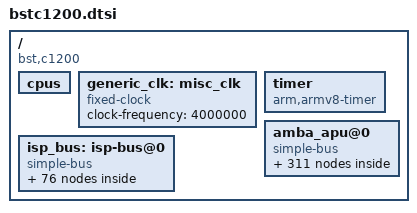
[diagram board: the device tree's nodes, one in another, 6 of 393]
// SPDX-License-Identifier: GPL-2.0+
/*
 * dts file for BlackSesame C1200
 *
 * (C) Copyright 2016 - 2024, BlackSesame, Inc.
 *
 * This program is free software; you can redistribute it and/or
 * modify it under the terms of the GNU General Public License as
 * published by the Free Software Foundation; either version 2 of
 * the License, or (at your option) any later version.
 */
#include <dt-bindings/interrupt-controller/arm-gic.h>
#include <dt-bindings/gpio/gpio.h>
#include <dt-bindings/clock/bstc1200-scmi.h>
#include <dt-bindings/reset/bst-resets-scmi.h>

/ {
	compatible = "bst,c1200";
	#address-cells = <2>;
	#size-cells = <2>;

	cpus {
		#address-cells = <1>;
		#size-cells = <0>;
	};

	generic_clk:misc_clk {
		compatible = "fixed-clock";
		#clock-cells = <0x0>;
		clock-frequency = <4000000>;
		phandle = <0x2>;
	};


	timer {
		compatible = "arm,armv8-timer";
		interrupt-parent = <&gic600>;
		interrupts = <GIC_PPI 0xd (GIC_CPU_MASK_SIMPLE(8) | IRQ_TYPE_LEVEL_LOW)
						GIC_PPI 0xe (GIC_CPU_MASK_SIMPLE(8) | IRQ_TYPE_LEVEL_LOW)
						GIC_PPI 0xb (GIC_CPU_MASK_SIMPLE(8) | IRQ_TYPE_LEVEL_LOW)
						GIC_PPI 0xa (GIC_CPU_MASK_SIMPLE(8) | IRQ_TYPE_LEVEL_LOW)>;
	};




	amba_apu@0 {
		compatible = "simple-bus";
		#address-cells = <0x2>;
		#size-cells = <0x2>;
		ranges = <0x0 0x0 0x0 0x0 0xffffffff 0xffffffff>;

		cpufreq: cpufreq@0 {
			compatible = "bst,cpufreq-c1200";
			reg = <0 0x30002000 0 0x1000>;
			clocks= <&scmi_clk GATE_CPU0_MP4_CORE_EN>,
				<&scmi_clk GATE_LB_CPU1_MP4_CORE_CLK_EN>,
				<&scmi_clk GATE_LB_CPU_MP2_CORE_CLK_EN>;
			clock-names = "cluster0", "cluster1", "cluster2";
			#freq-domain-cells = <1>;
		};

		bst_hfe: hfe@0x2300b000 {
			compatible = "bst,c1200-hfe";
			status = "disable";
			reg = <0x0 0x2300b000 0x0 0x1000>;
			interrupt-parent = <&gic600>;
			interrupts = <GIC_SPI 193 IRQ_TYPE_LEVEL_HIGH>;
		};
		bst_ske: ske@0x2300a000 {
			compatible = "bst,c1200-ske";
			status = "disable";
			reg = <0x0 0x2300a000 0x0 0x1000>;
			interrupt-parent = <&gic600>;
			interrupts = <GIC_SPI 194 IRQ_TYPE_LEVEL_HIGH>;
		};
		bst_pke: pke@0x23008000 {
			compatible = "bst,c1200-pke";
			status = "disable";
			reg = <0x0 0x23008000 0x0 0x2000>;
			interrupt-parent = <&gic600>;
			interrupts = <GIC_SPI 195 IRQ_TYPE_LEVEL_HIGH>;
		};

		msgbox: bst-msgbox {
			status = "disable";
			compatible = "bst,bst-msgbox";
			reg =   <0x0 0x32a00000 0 0x100000>;
			interrupt-parent = <&gic600>;
			#mbox-cells = <0x1>;
		};

		hwrng: bst-rng {
			status = "disable";
			compatible = "bst,c1200-rng";
		};

	safety_command:safety{
        compatible = "bst,safety_command";
        status = "disable";
    };

	firmware_scmi:scmi {
		compatible = "arm,scmi-msgbox";
		#address-cells = <1>;
		#size-cells = <0>;
		status = "disable";

		scmi_devpd: protocol@11 {
				reg = <0x11>;
				#power-domain-cells = <1>;
		};

		scmi_reset:protocol@16 {
			reg=<0x16>;
			#reset-cells =<1>;
		};

		scmi_clk:protocol@14 {
			reg=<0x14>;
			#clock-cells=<1>;
		};

		scmi_voltage: protocol@17 {
			reg = <0x17>;
		};

		scmi_pinctrl: protocol@19 {
			reg = <0x19>;
			#pinctrl-cells = <0>;
			i2c5_pinctrl: i2c5_pinctrl {
				mux {
					pins = "SC_I2C5_SCL", "SC_I2C5_SDA";
					function = "i2c5";
				};
			};
			i2c6_pinctrl: i2c6_pinctrl {
				mux {
					pins = "SC_I2C6_SCL", "SC_I2C6_SDA";
					function = "i2c6";
				};
			};
			i2c7_pinctrl: i2c7_pinctrl {
				mux {
					pins = "SC_I2C7_SCL", "SC_I2C7_SDA";
					function = "i2c7";
				};
			};
        };

		
		scmi_channel:protocol@1a {
			reg=<0x1a>;
			#reset-cells =<1>;
		};
	};

                gdma0:dma-controller@31280000 {
                        #dma-cells = <1>;
                        status = "disable";
                        compatible = "bst,dw-axi-gdma";
                        reg = <0x0 0x31280000 0 0x3000>;
                        //clocks = <&clkc LB_GDMA_CORE_CLK>, <&clkc LB_GDMA_AXI_GACLK>;
                        //clock-names = "core-clk", "cfgr-clk";
                        //resets = <&rstc RST_GDMA_SW>;
                        //reset-names = "gdma_reset";
			snps,chan-start = <0>;
                        dma-channels = <32>;
                        snps,dma-masters = <1>;
                        snps,data-width = <4>;
                        snps,block-size = <1048576 1048576 1048576 1048576 1048576 1048576 1048576 1048576
                                           1048576 1048576 1048576 1048576 1048576 1048576 1048576 1048576
                                           1048576 1048576 1048576 1048576 1048576 1048576 1048576 1048576
                                           1048576 1048576 1048576 1048576 1048576 1048576 1048576 1048576>;

                        snps,priority = <31 30 29 28 27 26 25 24
                                                         23 22 21 20 19 18 17 16
                                                         15 14 13 12 11 10  9  8
                                                          7  6  5  4  3  2  1  0>;
                        snps,axi-max-burst-len = <15>;
                        interrupt-parent = <&gic600>;
			interrupts = <            GIC_SPI 385 (GIC_CPU_MASK_SIMPLE(8) | IRQ_TYPE_LEVEL_HIGH)
                                                  GIC_SPI 386 (GIC_CPU_MASK_SIMPLE(8) | IRQ_TYPE_LEVEL_HIGH)
                                                  GIC_SPI 387 (GIC_CPU_MASK_SIMPLE(8) | IRQ_TYPE_LEVEL_HIGH)
                                                  GIC_SPI 388 (GIC_CPU_MASK_SIMPLE(8) | IRQ_TYPE_LEVEL_HIGH)
                                                  GIC_SPI 389 (GIC_CPU_MASK_SIMPLE(8) | IRQ_TYPE_LEVEL_HIGH)
                                                  GIC_SPI 390 (GIC_CPU_MASK_SIMPLE(8) | IRQ_TYPE_LEVEL_HIGH)
                                                  GIC_SPI 391 (GIC_CPU_MASK_SIMPLE(8) | IRQ_TYPE_LEVEL_HIGH)
                                                  GIC_SPI 392 (GIC_CPU_MASK_SIMPLE(8) | IRQ_TYPE_LEVEL_HIGH)
                                                  GIC_SPI 393 (GIC_CPU_MASK_SIMPLE(8) | IRQ_TYPE_LEVEL_HIGH)
                                                  GIC_SPI 394 (GIC_CPU_MASK_SIMPLE(8) | IRQ_TYPE_LEVEL_HIGH)
                                                  GIC_SPI 395 (GIC_CPU_MASK_SIMPLE(8) | IRQ_TYPE_LEVEL_HIGH)
                                                  GIC_SPI 396 (GIC_CPU_MASK_SIMPLE(8) | IRQ_TYPE_LEVEL_HIGH)
                                                  GIC_SPI 397 (GIC_CPU_MASK_SIMPLE(8) | IRQ_TYPE_LEVEL_HIGH)
                                                  GIC_SPI 398 (GIC_CPU_MASK_SIMPLE(8) | IRQ_TYPE_LEVEL_HIGH)
                                                  GIC_SPI 399 (GIC_CPU_MASK_SIMPLE(8) | IRQ_TYPE_LEVEL_HIGH)
                                                  GIC_SPI 400 (GIC_CPU_MASK_SIMPLE(8) | IRQ_TYPE_LEVEL_HIGH)
                                                  GIC_SPI 401 (GIC_CPU_MASK_SIMPLE(8) | IRQ_TYPE_LEVEL_HIGH)
                                                  GIC_SPI 402 (GIC_CPU_MASK_SIMPLE(8) | IRQ_TYPE_LEVEL_HIGH)
                                                  GIC_SPI 403 (GIC_CPU_MASK_SIMPLE(8) | IRQ_TYPE_LEVEL_HIGH)
                                                  GIC_SPI 404 (GIC_CPU_MASK_SIMPLE(8) | IRQ_TYPE_LEVEL_HIGH)
                                                  GIC_SPI 405 (GIC_CPU_MASK_SIMPLE(8) | IRQ_TYPE_LEVEL_HIGH)
                                                  GIC_SPI 406 (GIC_CPU_MASK_SIMPLE(8) | IRQ_TYPE_LEVEL_HIGH)
                                                  GIC_SPI 407 (GIC_CPU_MASK_SIMPLE(8) | IRQ_TYPE_LEVEL_HIGH)
                                                  GIC_SPI 408 (GIC_CPU_MASK_SIMPLE(8) | IRQ_TYPE_LEVEL_HIGH)
                                                  GIC_SPI 409 (GIC_CPU_MASK_SIMPLE(8) | IRQ_TYPE_LEVEL_HIGH)
                                                  GIC_SPI 410 (GIC_CPU_MASK_SIMPLE(8) | IRQ_TYPE_LEVEL_HIGH)
                                                  GIC_SPI 411 (GIC_CPU_MASK_SIMPLE(8) | IRQ_TYPE_LEVEL_HIGH)
                                                  GIC_SPI 412 (GIC_CPU_MASK_SIMPLE(8) | IRQ_TYPE_LEVEL_HIGH)
                                                  GIC_SPI 413 (GIC_CPU_MASK_SIMPLE(8) | IRQ_TYPE_LEVEL_HIGH)
                                                  GIC_SPI 414 (GIC_CPU_MASK_SIMPLE(8) | IRQ_TYPE_LEVEL_HIGH)
                                                  GIC_SPI 415 (GIC_CPU_MASK_SIMPLE(8) | IRQ_TYPE_LEVEL_HIGH)
                                                  GIC_SPI 416 (GIC_CPU_MASK_SIMPLE(8) | IRQ_TYPE_LEVEL_HIGH)>;
                };



// Cfg_LIO_system	0:2000:0000
// lsp0_crm_reg 2000:0000
		i2c0: i2c@20001000 {
			#address-cells = <1>;
			#size-cells = <0>;
			compatible = "snps,designware-i2c";
			reg = <0x0 0x20001000 0 0x1000>;
			interrupt-parent = <&gic600>;
			interrupts = <GIC_SPI 202 IRQ_TYPE_LEVEL_HIGH>;
			clock-frequency = <100000>;
			i2c-sda-hold-time-ns = <560>;
			i2c-sda-falling-time-ns = <560>;
			i2c-scl-falling-time-ns = <560>;
			i2c-digital-filter-width-ns = <50>;
			
			clocks= <&scmi_clk GATE_LSP0_I2C0_PCLK_EN>,
			<&scmi_clk GATE_LSP0_I2C0_WCLK_EN>;
			clock-names = "pclk","wclk";
			resets = <&scmi_reset RST_LSP0_I2C0_WCLK_SW>;
			reset-names = "i2c0_reset";

			i2c-nr = <0>;
			status = "disable";
		};

		i2c1: i2c@20002000 {
			#address-cells = <1>;
			#size-cells = <0>;
			compatible = "snps,designware-i2c";
			reg = <0x0 0x20002000 0 0x1000>;
			interrupt-parent = <&gic600>;
			interrupts = <GIC_SPI 203 IRQ_TYPE_LEVEL_HIGH>;
			clock-frequency = <100000>;
			i2c-sda-hold-time-ns = <560>;
			i2c-sda-falling-time-ns = <560>;
			i2c-scl-falling-time-ns = <560>;
			i2c-digital-filter-width-ns = <50>;

			clocks= <&scmi_clk GATE_LSP0_I2C1_PCLK_EN>,
			<&scmi_clk GATE_LSP0_I2C1_WCLK_EN>;
			clock-names = "pclk","wclk";
			resets = <&scmi_reset RST_LSP0_I2C1_WCLK_SW>;
			reset-names = "i2c0_reset";

			i2c-nr = <1>;
			status = "disable";
		};

		i2c2: i2c@20003000 {
			#address-cells = <1>;
			#size-cells = <0>;
			compatible = "snps,designware-i2c";
			reg = <0x0 0x20003000 0 0x1000>;
			interrupt-parent = <&gic600>;
			interrupts = <GIC_SPI 204 IRQ_TYPE_LEVEL_HIGH>;
			clock-frequency = <100000>;
			i2c-sda-hold-time-ns = <560>;
			i2c-sda-falling-time-ns = <560>;
			i2c-scl-falling-time-ns = <560>;
			i2c-digital-filter-width-ns = <50>;

			clocks= <&scmi_clk GATE_LSP0_I2C2_PCLK_EN>,
			<&scmi_clk GATE_LSP0_I2C2_WCLK_EN>;
			clock-names = "pclk","wclk";
			resets = <&scmi_reset RST_LSP0_I2C2_WCLK_SW>;
			reset-names = "i2c0_reset";

			i2c-nr = <2>;
			status = "disable";
		};



		i2c3: i2c@20004000 {
			#address-cells = <1>;
			#size-cells = <0>;
			compatible = "snps,designware-i2c";
			reg = <0x0 0x20004000 0 0x1000>;
			interrupt-parent = <&gic600>;
			interrupts = <GIC_SPI 205 IRQ_TYPE_LEVEL_HIGH>;
			clock-frequency = <100000>;
			i2c-sda-hold-time-ns = <560>;
			i2c-sda-falling-time-ns = <560>;
			i2c-scl-falling-time-ns = <560>;
			i2c-digital-filter-width-ns = <50>;

			clocks= <&scmi_clk GATE_LSP0_I2C3_PCLK_EN>,
			<&scmi_clk GATE_LSP0_I2C3_WCLK_EN>;
			clock-names = "pclk","wclk";
			resets = <&scmi_reset RST_LSP0_I2C3_WCLK_SW>;
			reset-names = "i2c0_reset";

			i2c-nr = <3>;
			status = "disable";
		};

		i2c4: i2c@20021000 {
			#address-cells = <1>;
			#size-cells = <0>;
			compatible = "snps,designware-i2c";
			reg = <0x0 0x20021000 0 0x1000>;
			interrupt-parent = <&gic600>;
			interrupts = <GIC_SPI 237 IRQ_TYPE_LEVEL_HIGH>;
			clock-frequency = <100000>;
			i2c-sda-hold-time-ns = <560>;
			i2c-sda-falling-time-ns = <560>;
			i2c-scl-falling-time-ns = <560>;
			i2c-digital-filter-width-ns = <50>;

			clocks= <&scmi_clk GATE_LSP1_I2C0_PCLK_EN>,
			<&scmi_clk GATE_LSP1_I2C0_WCLK_EN>;
			clock-names = "pclk","wclk";
			resets = <&scmi_reset RST_LSP1_I2C0_WCLK_SW>;
			reset-names = "i2c0_reset";

			i2c-nr = <4>;
			status = "disable";
		};

		i2c5: i2c@20022000 {
			#address-cells = <1>;
			#size-cells = <0>;
			compatible = "snps,designware-i2c";
			reg = <0x0 0x20022000 0 0x1000>;
			interrupt-parent = <&gic600>;
			interrupts = <GIC_SPI 238 IRQ_TYPE_LEVEL_HIGH>;
			clock-frequency = <100000>;
			i2c-sda-hold-time-ns = <560>;
			i2c-sda-falling-time-ns = <560>;
			i2c-scl-falling-time-ns = <560>;
			i2c-digital-filter-width-ns = <50>;

			clocks= <&scmi_clk GATE_LSP1_I2C1_PCLK_EN>,
			<&scmi_clk GATE_LSP1_I2C1_WCLK_EN>;
			clock-names = "pclk","wclk";
			resets = <&scmi_reset RST_LSP1_I2C1_WCLK_SW>;
			reset-names = "i2c0_reset";

			i2c-nr = <5>;
			ipc-sem = <1 1 7>;
			pinctrl-names = "default";
			pinctrl-0 = <&i2c5_pinctrl>;
			status = "disable";
		};

		i2c6: i2c@20023000 {
			#address-cells = <1>;
			#size-cells = <0>;
			compatible = "snps,designware-i2c";
			reg = <0x0 0x20023000 0 0x1000>;
			interrupt-parent = <&gic600>;
			interrupts = <GIC_SPI 239 IRQ_TYPE_LEVEL_HIGH>;
			clock-frequency = <100000>;
			i2c-sda-hold-time-ns = <560>;
			i2c-sda-falling-time-ns = <560>;
			i2c-scl-falling-time-ns = <560>;
			i2c-digital-filter-width-ns = <50>;

			clocks= <&scmi_clk GATE_LSP1_I2C2_PCLK_EN>,
			<&scmi_clk GATE_LSP1_I2C2_WCLK_EN>;
			clock-names = "pclk","wclk";
			resets = <&scmi_reset RST_LSP1_I2C2_WCLK_SW>;
			reset-names = "i2c0_reset";

			i2c-nr = <6>;
			ipc-sem = <1 1 8>;
			pinctrl-names = "default";
			pinctrl-0 = <&i2c6_pinctrl>;
			status = "disable";
		};

		i2c7: i2c@20024000 {
			#address-cells = <1>;
			#size-cells = <0>;
			compatible = "snps,designware-i2c";
			reg = <0x0 0x20024000 0 0x1000>;
			interrupt-parent = <&gic600>;
			interrupts = <GIC_SPI 240 IRQ_TYPE_LEVEL_HIGH>;
			clock-frequency = <100000>;
			i2c-sda-hold-time-ns = <560>;
			i2c-sda-falling-time-ns = <560>;
			i2c-scl-falling-time-ns = <560>;
			i2c-digital-filter-width-ns = <50>;

			clocks= <&scmi_clk GATE_LSP1_I2C3_PCLK_EN>,
			<&scmi_clk GATE_LSP1_I2C3_WCLK_EN>;
			clock-names = "pclk","wclk";
			resets = <&scmi_reset RST_LSP1_I2C3_WCLK_SW>;
			reset-names = "i2c0_reset";

			i2c-nr = <7>;
			ipc-sem = <1 1 9>;
			pinctrl-names = "default";
			pinctrl-0 = <&i2c7_pinctrl>;
			status = "disable";
		};


        i3c0: i3c@20012000 {
            reg = <0x0 0x20012000 0 0x1000>;
            compatible = "silvaco,i3c-master";
            // clocks = <&zynqmp_clk 71>, <&fclk>, <&sclk>;
            // clock-names = "pclk", "fast_clk", "slow_clk";
            interrupt-parent = <&gic600>;
            interrupts = <GIC_SPI 230 IRQ_TYPE_LEVEL_HIGH>;
            #address-cells = <3>;
            #size-cells = <0>;
			i2c-nr = <30>;
            status = "disable";
        };
        i3c1: i3c@20013000 {
            reg = <0x0 0x20013000 0 0x1000>;
            compatible = "silvaco,i3c-master";
            // clocks = <&zynqmp_clk 71>, <&fclk>, <&sclk>;
            // clock-names = "pclk", "fast_clk", "slow_clk";
            interrupt-parent = <&gic600>;
            interrupts = <GIC_SPI 231 IRQ_TYPE_LEVEL_HIGH>;
            #address-cells = <3>;
            #size-cells = <0>;
			i2c-nr = <31>;
            status = "disable";
        };
        i3c2: i3c@20032000 {
            reg = <0x0 0x20032000 0 0x1000>;
            compatible = "silvaco,i3c-master";
            // clocks = <&zynqmp_clk 71>, <&fclk>, <&sclk>;
            // clock-names = "pclk", "fast_clk", "slow_clk";
            interrupt-parent = <&gic600>;
            interrupts = <GIC_SPI 265 IRQ_TYPE_LEVEL_HIGH>;
            #address-cells = <3>;
            #size-cells = <0>;
			i2c-nr = <32>;
            status = "disable";
        };
        i3c3: i3c@20033000 {
            reg = <0x0 0x20033000 0 0x1000>;
            compatible = "silvaco,i3c-master";
            // clocks = <&zynqmp_clk 71>, <&fclk>, <&sclk>;
            // clock-names = "pclk", "fast_clk", "slow_clk";
            interrupt-parent = <&gic600>;
            interrupts = <GIC_SPI 266 IRQ_TYPE_LEVEL_HIGH>;
            #address-cells = <3>;
            #size-cells = <0>;
			i2c-nr = <33>;
            status = "disable";
        };
		uart0:serial@20007000 {
			compatible = "snps,dw-apb-uart";
			reg = <0x0 0x20007000 0 0x1000>;
			interrupt-parent = <&gic600>;
			interrupts = <GIC_SPI 210 IRQ_TYPE_LEVEL_HIGH>;

			clocks = <&scmi_clk GATE_LSP0_UART0_WCLK_EN>, <&scmi_clk GATE_LSP0_UART0_PCLK_EN>;
			clock-names = "baudclk","apb_pclk";

			resets = <&scmi_reset RST_LSP0_UART0_WCLK_SW>;
			reset-names = "uart_reset";


			reg-shift = <2>;
			reg-io-width = <4>;
			status = "disable";
		};

		uart1: serial@20008000 {
			compatible = "snps,dw-apb-uart";
			reg = <0 0x20008000 0 0x1000>;
			interrupt-parent = <&gic600>;
			interrupts = <GIC_SPI 211 IRQ_TYPE_LEVEL_HIGH>;
			
			clocks = <&scmi_clk GATE_LSP0_UART1_WCLK_EN>, <&scmi_clk GATE_LSP0_UART1_PCLK_EN>;
			clock-names = "baudclk","apb_pclk";

			resets = <&scmi_reset RST_LSP0_UART1_WCLK_SW>;
			reset-names = "uart_reset";
	

			reg-shift = <2>;
			reg-io-width = <4>;
			status = "disable";
		};

		uart2:serial@20027000 {
			compatible = "snps,dw-apb-uart";
			reg = <0x0 0x20027000 0 0x1000>;
			interrupt-parent = <&gic600>;
			interrupts = <GIC_SPI 245 IRQ_TYPE_LEVEL_HIGH>;
			
			clocks = <&scmi_clk GATE_LSP1_UART0_WCLK_EN>, <&scmi_clk GATE_LSP1_UART0_PCLK_EN>;
			clock-names = "baudclk","apb_pclk";

			resets = <&scmi_reset RST_LSP1_UART0_WCLK_SW>;
			reset-names = "uart_reset";


			reg-shift = <2>;
			reg-io-width = <4>;
			status = "disable";
		};

		uart3:serial@20028000 {
			compatible = "snps,dw-apb-uart";
			reg = <0x0 0x20028000 0 0x1000>;
			interrupt-parent = <&gic600>;
			interrupts = <GIC_SPI 246 IRQ_TYPE_LEVEL_HIGH>;
					
			clocks = <&scmi_clk GATE_LSP1_UART1_WCLK_EN>, <&scmi_clk GATE_LSP1_UART1_PCLK_EN>;
			clock-names = "baudclk","apb_pclk";

			resets = <&scmi_reset RST_LSP1_UART1_WCLK_SW>;
			reset-names = "uart_reset";

			reg-shift = <2>;
			reg-io-width = <4>;
			status = "disable";
		};

		/* lsp0-ssi-m */
		spi0: spi@20009000 {
			status = "disable";
			compatible = "snps,dw-apb-ssi";
			#address-cells = <1>;
			#size-cells = <0>;
			reg = <0x0 0x20009000 0 0x1000>;
			interrupt-parent = <&gic600>;
			interrupts = <GIC_SPI 208 IRQ_TYPE_LEVEL_HIGH>;
			clocks= <&scmi_clk GATE_LSP0_SSI_M_WCLK_EN>,
				<&scmi_clk GATE_LSP0_SSI_M_PCLK_EN>;
			clock-names = "wclk", "pclk";
			resets = <&scmi_reset RST_LSP0_SSI_M_WCLK_SW>;
			reset-names = "spi";
			num-cs = <1>;
			bus-num = <0>;
			dmas = <&gdma0 59>,
			       <&gdma0 58>;
			dma-names = "tx", "rx";
		};

		/* lsp0-ssi-s */
		spi1: spi@2000a000 {
			status = "disable";
			spi-slave;
			compatible = "snps,dw-apb-ssi";
			#address-cells = <0>;
			#size-cells = <0>;
			reg = <0x0 0x2000a000 0 0x1000>;
			interrupt-parent = <&gic600>;
			interrupts = <GIC_SPI 209 IRQ_TYPE_LEVEL_HIGH>;
			clocks= <&scmi_clk GATE_LSP0_SSI_S_WCLK_EN>,
				<&scmi_clk GATE_LSP0_SSI_S_PCLK_EN>;
			clock-names = "wclk", "pclk";
			resets = <&scmi_reset RST_LSP0_SSI_S_WCLK_SW>;
			reset-names = "spi";
			num-cs = <1>;
			bus-num = <0>;
			dmas = <&gdma0 57>,
			       <&gdma0 56>;
			dma-names = "tx", "rx";
		};

		/* lsp1-ssi-m */
		spi2: spi@20029000 {
			status = "disable";
			compatible = "snps,dw-apb-ssi";
			#address-cells = <1>;
			#size-cells = <0>;
			reg = <0x0 0x20029000 0 0x1000>;
			interrupt-parent = <&gic600>;
			interrupts = <GIC_SPI 243 IRQ_TYPE_LEVEL_HIGH>;
			clocks= <&scmi_clk GATE_LSP1_SSI_M_WCLK_EN>,
				<&scmi_clk GATE_LSP1_SSI_M_PCLK_EN>;
			clock-names = "wclk", "pclk";
			resets = <&scmi_reset RST_LSP1_SSI_M_WCLK_SW>;
			reset-names = "spi";
			num-cs = <1>;
			bus-num = <1>;
			dmas = <&gdma0 27>,
			       <&gdma0 26>;
			dma-names = "tx", "rx";
		};

		/* lsp1-ssi-s */
		spi3: spi@2002a000 {
			status = "disable";
			spi-slave;
			compatible = "snps,dw-apb-ssi";
			#address-cells = <0>;
			#size-cells = <0>;
			reg = <0x0 0x2002a000 0 0x1000>;
			interrupt-parent = <&gic600>;
			interrupts = <GIC_SPI 244 IRQ_TYPE_LEVEL_HIGH>;
			clocks= <&scmi_clk GATE_LSP1_SSI_S_WCLK_EN>,
				<&scmi_clk GATE_LSP1_SSI_S_PCLK_EN>;
			clock-names = "wclk", "pclk";
			resets = <&scmi_reset RST_LSP1_SSI_S_WCLK_SW>;
			reset-names = "spi";
			num-cs = <1>;
			bus-num = <1>;
			dmas = <&gdma0 25>,
			       <&gdma0 24>;
			dma-names = "tx", "rx";
		};

		i2s0:i2s@2000b000 {
			compatible = "snps,designware-i2s";
			reg = <0x0 0x2000b000 0 0x1000>;
			interrupt-names = "i2s0_irq";
			interrupt-parent = <&gic600>;
			interrupts = <GIC_SPI 226 IRQ_TYPE_LEVEL_HIGH>;
			clocks= <&scmi_clk GATE_LSP0_I2S0_WCLK_EN>,
				<&scmi_clk GATE_LSP0_I2S0_PCLK_EN>;
			clock-names = "wclk", "pclk";
			//use-dma;
			//slave-mode;
			dmas = <&gdma0 48>,
					<&gdma0 44>;
			dma-names = "tx", "rx";
			#sound-dai-cells = <0>;
			status = "disable";
		};

		i2s1:i2s@2000c000 {
			compatible = "snps,designware-i2s";
			reg = <0x0 0x2000c000 0 0x1000>;
			interrupt-names = "i2s1_irq";
			interrupt-parent = <&gic600>;
			interrupts = <GIC_SPI 227 IRQ_TYPE_LEVEL_HIGH>;
			clocks= <&scmi_clk GATE_LSP0_I2S1_WCLK_EN>,
				<&scmi_clk GATE_LSP0_I2S1_PCLK_EN>;
			clock-names = "wclk", "pclk";
			//use-dma;
			dmas = <&gdma0 40>,
			       <&gdma0 36>;
			dma-names = "tx", "rx";
			#sound-dai-cells = <0>;
			status = "disable";
		};

		i2s2:i2s@2002b000 {
			compatible = "snps,designware-i2s";
			reg = <0x0 0x2002b000 0 0x1000>;
			interrupt-names = "i2s2_irq";
			interrupt-parent = <&gic600>;
			interrupts = <GIC_SPI 261 IRQ_TYPE_LEVEL_HIGH>;
			clocks= <&scmi_clk GATE_LSP1_I2S1_WCLK_EN>,
				<&scmi_clk GATE_LSP1_I2S1_PCLK_EN>;
			clock-names = "wclk", "pclk";
			//use-dma;
			//slave-mode;
			dmas = <&gdma0 16>,
			       <&gdma0 12>;
			dma-names = "tx", "rx";
			#sound-dai-cells = <0>;
			status = "disable";
		};

		i2s3:i2s@2002c000 {
			compatible = "snps,designware-i2s";
			reg = <0x0 0x2002c000 0 0x1000>;
			interrupt-names = "i2s3_irq";
			interrupt-parent = <&gic600>;
			interrupts = <GIC_SPI 262 IRQ_TYPE_LEVEL_HIGH>;
			//use-dma;
			dmas = <&gdma0 8>,
			       <&gdma0 4>;
			dma-names = "tx", "rx";
			#sound-dai-cells = <0>;
			status = "disable";
		};

		tdm0:tdm@2000d000 {
			compatible = "snps,designware-tdm";
			reg = <0x0 0x2000d000 0 0x1000>;
			interrupt-names = "tdm0_irq";
			interrupt-parent = <&gic600>;
			interrupts = <GIC_SPI 228 IRQ_TYPE_LEVEL_HIGH>;
			clocks= <&scmi_clk GATE_LSP0_TDM0_WCLK_EN>,
				<&scmi_clk GATE_LSP0_TDM0_PCLK_EN>;
			clock-names = "wclk", "pclk";
			dmas = <&gdma0 35>,
			       <&gdma0 34>;
			dma-names = "tx", "rx";
			#sound-dai-cells = <0>;
			status = "disable";
		};

		tdm1:tdm@2000e000 {
			compatible = "snps,designware-tdm";
			reg = <0x0 0x2000e000 0 0x1000>;
			interrupt-names = "tdm1_irq";
			interrupt-parent = <&gic600>;
			interrupts = <GIC_SPI 229 IRQ_TYPE_LEVEL_HIGH>;
			clocks= <&scmi_clk GATE_LSP0_TDM1_WCLK_EN>,
				<&scmi_clk GATE_LSP0_TDM1_PCLK_EN>;
			clock-names = "wclk", "pclk";
			dmas = <&gdma0 33>,
			       <&gdma0 32>;
			dma-names = "tx", "rx";
			#sound-dai-cells = <0>;
			status = "disable";
		};

		tdm2:tdm@2002d000 {
			compatible = "snps,designware-tdm";
			reg = <0x0 0x2002d000 0 0x1000>;
			interrupt-names = "tdm2_irq";
			interrupt-parent = <&gic600>;
			interrupts = <GIC_SPI 263 IRQ_TYPE_LEVEL_HIGH>;
			clocks= <&scmi_clk GATE_LSP1_TDM0_WCLK_EN>,
				<&scmi_clk GATE_LSP1_TDM0_PCLK_EN>;
			clock-names = "wclk", "pclk";
			dmas = <&gdma0 3>,
			       <&gdma0 2>;
			dma-names = "tx", "rx";
			#sound-dai-cells = <0>;
			status = "disable";
		};

		tdm3:tdm@2002e000 {
			compatible = "snps,designware-tdm";
			reg = <0x0 0x2002e000 0 0x1000>;
			interrupt-names = "tdm3_irq";
			interrupt-parent = <&gic600>;
			interrupts = <GIC_SPI 264 IRQ_TYPE_LEVEL_HIGH>;
			clocks= <&scmi_clk GATE_LSP1_TDM1_WCLK_EN>,
				<&scmi_clk GATE_LSP1_TDM1_PCLK_EN>;
			clock-names = "wclk", "pclk";
			dmas = <&gdma0 1>,
			       <&gdma0 0>;
			dma-names = "tx", "rx";
			#sound-dai-cells = <0>;
			status = "disable";
		};

		watchdog0: watchdog@2000f000 {
			compatible = "snps,dw-wdt";
			reg = <0x0 0x2000f000 0 0x1000>;
			interrupt-parent = <&gic600>;
			interrupts = <GIC_SPI 212 IRQ_TYPE_LEVEL_HIGH>;
                        clocks= <&scmi_clk GATE_LSP0_WDT0_PCLK_EN>,
                               <&scmi_clk GATE_LSP0_WDT0_WCLK_EN>;
                        clock-names = "pclk","wclk";
                        response-mode = <0x1>;

			bst_wdt_name = "lsp_wdt0";
			status = "disable";
		};

		watchdog1: watchdog@20010000 {
			compatible = "snps,dw-wdt";
			reg = <0x0 0x20010000 0 0x1000>;
			interrupt-parent = <&gic600>;
			interrupts = <GIC_SPI 213 IRQ_TYPE_LEVEL_HIGH>;
                        response-mode = <0x1>;
                        clocks= <&scmi_clk GATE_LSP0_WDT1_PCLK_EN>,
                                <&scmi_clk GATE_LSP0_WDT1_WCLK_EN>;
                        clock-names = "pclk","wclk";

			bst_wdt_name = "lsp_wdt1";
			status = "disable";
		};

		watchdog2: watchdog@2002f000 {
			compatible = "snps,dw-wdt";
			reg = <0x0 0x2002f000 0 0x1000>;
			interrupt-parent = <&gic600>;
			interrupts = <GIC_SPI 247 IRQ_TYPE_LEVEL_HIGH>;
                        response-mode = <0x1>;
                        clocks= <&scmi_clk GATE_LSP1_WDT0_PCLK_EN>,
                               <&scmi_clk GATE_LSP1_WDT0_WCLK_EN>;
                        clock-names = "pclk","wclk";

			bst_wdt_name = "lsp_wdt2";
			status = "disable";
		};

		watchdog3: watchdog@20030000 {
			compatible = "snps,dw-wdt";
			reg = <0x0 0x20030000 0 0x1000>;
			interrupt-parent = <&gic600>;
			interrupts = <GIC_SPI 248 IRQ_TYPE_LEVEL_HIGH>;
                        response-mode = <0x1>;
                        clocks= <&scmi_clk GATE_LSP1_WDT1_PCLK_EN>,
                                <&scmi_clk GATE_LSP1_WDT1_WCLK_EN>;
                        clock-names = "pclk","wclk";

			bst_wdt_name = "lsp_wdt3";
			status = "disable";
		};

		watchdog_soc0: watchdog@32068000 {
			compatible = "snps,dw-wdt";
			reg = <0x0 0x32068000 0 0x1000>;
			interrupt-parent = <&gic600>;
                        interrupts = <GIC_PPI 0 IRQ_TYPE_LEVEL_HIGH>;
                        clocks= <&scmi_clk GATE_LB_CPU_PERIP_SYSNOC_APB_PCLK_EN>,
                                <&scmi_clk GATE_LB_CPU_PERIP_CLK_EN>;
                        clock-names = "pclk","wclk";

			response-mode = <0x0>;
			bst_wdt_name = "soc_a78_wdt0";
			status = "disable";
		};

		watchdog_soc1: watchdog@32069000 {
			compatible = "snps,dw-wdt";
			reg = <0x0 0x32069000 0 0x1000>;
			interrupt-parent = <&gic600>;
			response-mode = <0x0>;
                        interrupts = <GIC_PPI 0 IRQ_TYPE_LEVEL_HIGH>;
                        clocks= <&scmi_clk GATE_LB_CPU_PERIP_SYSNOC_APB_PCLK_EN>,
                                <&scmi_clk GATE_LB_CPU_PERIP_CLK_EN>;
                        clock-names = "pclk","wclk";
			bst_wdt_name = "soc_a78_wdt1";
			status = "disable";
		};

		watchdog_soc2: watchdog@3206a000 {
			compatible = "snps,dw-wdt";
			reg = <0x0 0x3206a000 0 0x1000>;
			interrupt-parent = <&gic600>;
                        interrupts = <GIC_PPI 0 IRQ_TYPE_LEVEL_HIGH>;
                        clocks= <&scmi_clk GATE_LB_CPU_PERIP_SYSNOC_APB_PCLK_EN>,
                                <&scmi_clk GATE_LB_CPU_PERIP_CLK_EN>;
                        clock-names = "pclk","wclk";
			response-mode = <0x0>;
			bst_wdt_name = "soc_a78_wdt2";
			status = "disable";
		};

		watchdog_soc3: watchdog@3206b000 {
			compatible = "snps,dw-wdt";
			reg = <0x0 0x3206b000 0 0x1000>;
			interrupt-parent = <&gic600>;
                        interrupts = <GIC_PPI 0 IRQ_TYPE_LEVEL_HIGH>;
                        clocks= <&scmi_clk GATE_LB_CPU_PERIP_SYSNOC_APB_PCLK_EN>,
                                <&scmi_clk GATE_LB_CPU_PERIP_CLK_EN>;
                        clock-names = "pclk","wclk";
			response-mode = <0x0>;
			bst_wdt_name = "soc_a78_wdt3";
			status = "disable";
		};

		watchdog_soc4: watchdog@3206c000 {
			compatible = "snps,dw-wdt";
			reg = <0x0 0x3206c000 0 0x1000>;
			interrupt-parent = <&gic600>;
                        interrupts = <GIC_PPI 0 IRQ_TYPE_LEVEL_HIGH>;
                        clocks= <&scmi_clk GATE_LB_CPU_PERIP_SYSNOC_APB_PCLK_EN>,
                                <&scmi_clk GATE_LB_CPU_PERIP_CLK_EN>;
                        clock-names = "pclk","wclk";
			response-mode = <0x0>;
			bst_wdt_name = "soc_a78_wdt0";
			status = "disable";
		};

		watchdog_soc5: watchdog@3206d000 {
			compatible = "snps,dw-wdt";
			reg = <0x0 0x3206d000 0 0x1000>;
			interrupt-parent = <&gic600>;
                        interrupts = <GIC_PPI 0 IRQ_TYPE_LEVEL_HIGH>;
                        clocks= <&scmi_clk GATE_LB_CPU_PERIP_SYSNOC_APB_PCLK_EN>,
                                <&scmi_clk GATE_LB_CPU_PERIP_CLK_EN>;
                        clock-names = "pclk","wclk";
			response-mode = <0x0>;
			bst_wdt_name = "soc_a78_wdt1";
			status = "disable";
		};

		watchdog_soc6: watchdog@3206e000 {
			compatible = "snps,dw-wdt";
			reg = <0x0 0x3206e000 0 0x1000>;
			interrupt-parent = <&gic600>;
                        interrupts = <GIC_PPI 0 IRQ_TYPE_LEVEL_HIGH>;
                        clocks= <&scmi_clk GATE_LB_CPU_PERIP_SYSNOC_APB_PCLK_EN>,
                                <&scmi_clk GATE_LB_CPU_PERIP_CLK_EN>;
                        clock-names = "pclk","wclk";
			response-mode = <0x0>;
			bst_wdt_name = "soc_a78_wdt2";
			status = "disable";
		};

		watchdog_soc7: watchdog@3206f000 {
			compatible = "snps,dw-wdt";
			reg = <0x0 0x3206f000 0 0x1000>;
			interrupt-parent = <&gic600>;
                        interrupts = <GIC_PPI 0 IRQ_TYPE_LEVEL_HIGH>;
                        clocks= <&scmi_clk GATE_LB_CPU_PERIP_SYSNOC_APB_PCLK_EN>,
                                <&scmi_clk GATE_LB_CPU_PERIP_CLK_EN>;
                        clock-names = "pclk","wclk";
			response-mode = <0x0>;
			bst_wdt_name = "soc_a78_wdt3";
			status = "disable";
		};

		watchdog_db0: watchdog@33002000 {
			compatible = "snps,dw-wdt";
			reg = <0x0 0x33002000 0 0x1000>;
			interrupt-parent = <&gic600>;
			interrupts = <GIC_SPI 16 IRQ_TYPE_LEVEL_HIGH>;
			response-mode = <0x0>;
			bst_wdt_name = "db_a78_wdt0";
			timeout-sec = <10>;
			status = "disable";
		};

		watchdog_db1: watchdog@33003000 {
			compatible = "snps,dw-wdt";
			reg = <0x0 0x33003000 0 0x1000>;
			interrupt-parent = <&gic600>;
			interrupts = <GIC_SPI 18 IRQ_TYPE_LEVEL_HIGH>;
			response-mode = <0x0>;
			bst_wdt_name = "db_a78_wdt1";
			timeout-sec = <10>;
			status = "disable";
		};

		watchdog_db2: watchdog@33004000 {
			compatible = "snps,dw-wdt";
			reg = <0x0 0x33004000 0 0x1000>;
			interrupt-parent = <&gic600>;
			interrupts = <GIC_SPI 16 IRQ_TYPE_LEVEL_HIGH>;
			response-mode = <0x0>;
			bst_wdt_name = "db_a78_wdt2";
			timeout-sec = <10>;
			status = "disable";
		};

		watchdog_db3: watchdog@33005000 {
			compatible = "snps,dw-wdt";
			reg = <0x0 0x33005000 0 0x1000>;
			interrupt-parent = <&gic600>;
			interrupts = <GIC_SPI 18 IRQ_TYPE_LEVEL_HIGH>;
			response-mode = <0x0>;
			bst_wdt_name = "db_a78_wdt3";
			timeout-sec = <10>;
			status = "disable";
		};

		lsp0_pwm0: lsp0_pwm0@20011000 {
			compatible = "snps,bst-pwm";
			clocks = <&scmi_clk GATE_LSP0_TIMER0_WCLK_EN>,
				 <&scmi_clk GATE_LSP0_TIMER_PCLK_EN>;
			clock-names = "wclk","pclk";
			clock-frequency = <25000000>;
			reg = <	0x0 0x20011000 0 0x14
					0x0 0x200110b0 0 0x4>;
			reg-names = "base", "top";
			pwm-ch = <1>;
			status = "disable";
		};

		lsp1_pwm0: lsp1_pwm0@20031000 {		// 8 channel
			status = "disable";
			compatible = "snps,bst-pwm";
			reg = <	0x0 0x20031000 0 0x14
					0x0 0x200310b0 0 0x4>;
			reg-names = "base", "top";
			pwm-ch = <1>;
		};
		// i3c  2001:2000 // 2001:3000 // 2003:2000 // 2003:3000
		// pwmin0 2001:4000 // 2003:4000
		// spdif 2001:5000 // 2001:6000 // 2003:5000 // 2003:6000

		gpio0: gpio@20017000 {
			status = "disable";
			#address-cells = <1>;
			#size-cells = <0>;
			compatible = "snps,dw-apb-gpio";
			reg = <0x0 0x20017000 0x0 0x1000>;

			clock-names = "bus","db";
			clocks = <&scmi_clk GATE_LSP0_GPIO0_DBCLK_EN>,<&scmi_clk GATE_LSP0_GPIO0_PCLK_EN>;

			porta: gpio-controller@0 {
				compatible = "snps,dw-apb-gpio-port";
				gpio-controller;
				#gpio-cells = <2>;
				snps,nr-gpios = <32>;
				reg = <0>;
				chipnum-base = <0>;
				interrupt-controller;
				#interrupt-cells = <3>;
				interrupt-parent = <&gic600>;
				interrupts = <GIC_SPI 217 (IRQ_TYPE_LEVEL_HIGH)>;
			};
		};

		gpio1: gpio@20018000 {
			status = "disable";
			#address-cells = <1>;
			#size-cells = <0>;
			compatible = "snps,dw-apb-gpio";
			reg = <0x0 0x20018000 0x0 0x1000>;

			clock-names = "bus","db";
			clocks = <&scmi_clk GATE_LSP0_GPIO1_DBCLK_EN>,<&scmi_clk GATE_LSP0_GPIO1_PCLK_EN>;

			portb: gpio-controller@0 {
				compatible = "snps,dw-apb-gpio-port";
				gpio-controller;
				#gpio-cells = <2>;
				snps,nr-gpios = <32>;
				reg = <0>;
				chipnum-base = <32>;
				interrupt-controller;
				#interrupt-cells = <3>;
				interrupt-parent = <&gic600>;
				interrupts = <GIC_SPI 217 (IRQ_TYPE_LEVEL_HIGH)>;
			};
		};

		gpio2: gpio@20019000 {
			status = "disable";
			#address-cells = <1>;
			#size-cells = <0>;
			compatible = "snps,dw-apb-gpio";
			reg = <0x0 0x20019000 0x0 0x1000>;

			clock-names = "bus","db";
			clocks = <&scmi_clk GATE_LSP0_GPIO2_DBCLK_EN>,<&scmi_clk GATE_LSP0_GPIO2_PCLK_EN>;

			portc: gpio-controller@0 {
				compatible = "snps,dw-apb-gpio-port";
				gpio-controller;
				#gpio-cells = <2>;
				snps,nr-gpios = <32>;
				reg = <0>;
				chipnum-base = <64>;
				interrupt-controller;
				#interrupt-cells = <3>;
				interrupt-parent = <&gic600>;
				interrupts = <GIC_SPI 217 (IRQ_TYPE_LEVEL_HIGH)>;
			};
		};

		gpio3: gpio@2001a000 {
			status = "disable";
			#address-cells = <1>;
			#size-cells = <0>;
			compatible = "snps,dw-apb-gpio";
			reg = <0x0 0x2001a000 0x0 0x1000>;

			clock-names = "bus","db";
			clocks = <&scmi_clk GATE_LSP0_GPIO3_DBCLK_EN>,<&scmi_clk GATE_LSP0_GPIO3_PCLK_EN>;

			portd: gpio-controller@0 {
				compatible = "snps,dw-apb-gpio-port";
				gpio-controller;
				#gpio-cells = <2>;
				snps,nr-gpios = <32>;
				reg = <0>;
				chipnum-base = <96>;
				interrupt-controller;
				#interrupt-cells = <3>;
				interrupt-parent = <&gic600>;
				interrupts = <GIC_SPI 217 (IRQ_TYPE_LEVEL_HIGH)>;
			};
		};

		gpio4: gpio@20037000 {
			status = "disable";
			#address-cells = <1>;
			#size-cells = <0>;
			compatible = "snps,dw-apb-gpio";
			reg = <0x0 0x20037000 0x0 0x1000>;

			clock-names = "bus","db";
			clocks = <&scmi_clk GATE_LSP1_GPIO0_DBCLK_EN>,<&scmi_clk GATE_LSP1_GPIO0_PCLK_EN>;

			porte: gpio-controller@0 {
				compatible = "snps,dw-apb-gpio-port";
				gpio-controller;
				#gpio-cells = <2>;
				snps,nr-gpios = <32>;
				reg = <0>;
				chipnum-base = <128>;
				interrupt-controller;
				#interrupt-cells = <3>;
				interrupt-parent = <&gic600>;
				interrupts = <GIC_SPI 252 (IRQ_TYPE_LEVEL_HIGH)>;
			};
		};

		gpio5: gpio@20038000 {
			status = "disable";
			#address-cells = <1>;
			#size-cells = <0>;
			compatible = "snps,dw-apb-gpio";
			reg = <0x0 0x20038000 0x0 0x1000>;

			//clock-names = "bus","db";
			//clocks = <&scmi_clk GATE_LSP1_GPIO1_DBCLK_EN>,<&scmi_clk GATE_LSP1_GPIO1_PCLK_EN>;

			portf: gpio-controller@0 {
				compatible = "snps,dw-apb-gpio-port";
				gpio-controller;
				#gpio-cells = <2>;
				snps,nr-gpios = <32>;
				reg = <0>;
				chipnum-base = <160>;
				interrupt-controller;
				#interrupt-cells = <3>;
				interrupt-parent = <&gic600>;
				interrupts = <GIC_SPI 252 (IRQ_TYPE_LEVEL_HIGH)>;
			};
		};

		gpio6: gpio@20039000 {
			status = "disable";
			#address-cells = <1>;
			#size-cells = <0>;
			compatible = "snps,dw-apb-gpio";
			reg = <0x0 0x20039000 0x0 0x1000>;

			clock-names = "bus","db";
			clocks = <&scmi_clk GATE_LSP1_GPIO2_DBCLK_EN>,<&scmi_clk GATE_LSP1_GPIO2_PCLK_EN>;

			portg: gpio-controller@0 {
				compatible = "snps,dw-apb-gpio-port";
				gpio-controller;
				#gpio-cells = <2>;
				snps,nr-gpios = <32>;
				reg = <0>;
				chipnum-base = <192>;
				interrupt-controller;
				#interrupt-cells = <3>;
				interrupt-parent = <&gic600>;
				interrupts = <GIC_SPI 252 (IRQ_TYPE_LEVEL_HIGH)>;
			};
		};

		gpio7: gpio@2003a000 {
			status = "disable";
			#address-cells = <1>;
			#size-cells = <0>;
			compatible = "snps,dw-apb-gpio";
			reg = <0x0 0x2003a000 0x0 0x1000>;

			clock-names = "bus","db";
			clocks = <&scmi_clk GATE_LSP1_GPIO3_DBCLK_EN>,<&scmi_clk GATE_LSP1_GPIO3_PCLK_EN>;

			porth: gpio-controller@0 {
				compatible = "snps,dw-apb-gpio-port";
				gpio-controller;
				#gpio-cells = <2>;
				snps,nr-gpios = <32>;
				reg = <0>;
				chipnum-base = <224>;
				interrupt-controller;
				#interrupt-cells = <3>;
				interrupt-parent = <&gic600>;
				interrupts = <GIC_SPI 252 (IRQ_TYPE_LEVEL_HIGH)>;
			};
		};

		gpiokeys: gpio-keys@0 {
			status = "disable";
			compatible = "gpio-keys";
			#address-cells = <1>;
			#size-cells = <0>;
			key0 {
				label = "GPIO Key Enter";
				linux,code = <28>;
				linux,input-type = <1>;
				gpios = <&portf 11 GPIO_ACTIVE_LOW>;
				wakeup-source;
			};
		};

		thermal: thermal {
				status = "disable";
				compatible = "bst,bst-thermal";
				#thermal-sensor-cells = <0>;
				//simpwm-gpios = <&porta 10 GPIO_ACTIVE_HIGH>;
		};

		can0: can@21710000 {
			status = "disable";
			compatible = "bst,bst-flexcan";
			reg = <0x0 0x21710000 0x0 0x8000>;
			interrupt-parent = <&gic600>;
			interrupts = <GIC_SPI 480 IRQ_TYPE_LEVEL_HIGH>;
			clock-frequency = <80000000>;
			fsl,clk-source = <0>;
			mailbox-tx-num = <64>;
			dmas = <&gdma0 0>;
			dma-names = "rx";
		};
		can1: can@21718000 {
			status = "disable";
			compatible = "bst,bst-flexcan";
			reg = <0x0 0x21718000 0x0 0x8000>;
			interrupt-parent = <&gic600>;
			interrupts = <GIC_SPI 481 IRQ_TYPE_LEVEL_HIGH>;
			clock-frequency = <80000000>;
			fsl,clk-source = <0>;
			mailbox-tx-num = <64>;
			dmas = <&gdma0 1>;
			dma-names = "rx";
		};

		// flexray 2001:B000 // 2003:B000
		// lsp1_crm_reg 2002:0000
		// smbus2 2002:5000 // 2002:6000

		swdma0:dma-controller@217E0000 {
			status = "disable";
			#dma-cells = <1>;
			compatible = "bst,dw-axi-gdma";
			reg = <0x0 0x217E0000 0 0x1000>;
			dma-channels = <4>;
			snps,dma-masters = <1>;
			snps,data-width = <4>;
			snps,block-size = <4096 4096 4096 4096>;
			snps,priority = <3  2  1  0>;
			snps,axi-max-burst-len = <16>;
			interrupt-parent = <&gic600>;
			interrupts = <GIC_SPI 487 (GIC_CPU_MASK_SIMPLE(8) | IRQ_TYPE_LEVEL_HIGH)
						  GIC_SPI 483 (GIC_CPU_MASK_SIMPLE(8) | IRQ_TYPE_LEVEL_HIGH)
						  GIC_SPI 484 (GIC_CPU_MASK_SIMPLE(8) | IRQ_TYPE_LEVEL_HIGH)
						  GIC_SPI 485 (GIC_CPU_MASK_SIMPLE(8) | IRQ_TYPE_LEVEL_HIGH)
						  GIC_SPI 486 (GIC_CPU_MASK_SIMPLE(8) | IRQ_TYPE_LEVEL_HIGH)>;
		};

		// Cfg_HIO_system
		usb3_phy: phy@23003000 {
			compatible = "bst,dwc-usb-phy";
			reg = <0x0 0x23003000 0 0x1000>;
			#phy-cells = <0>;
			usb_mode = "usb31";
			pll_type = "external";
			host_force_gen1_speed;
		};

		usb2_phy: phy@23004000 {
			compatible = "bst,dwc-usb-phy";
			#phy-cells = <0>;
			reg = <0x0 0x23004000 0 0x1000>;
			usb_mode = "usb31";
			pll_type = "external";
			is_typec_phy;
			host_force_gen1_speed;
		};

		usbdrd_dwc3: usb3 {
			compatible = "bst,dwc3usb";
			status = "disable";
			ranges;
			#address-cells = <2>;
			#size-cells = <2>;
			clock-names = "u2phyref","ref", "ctrlref", "axi", "apb";
			clocks = <&scmi_clk GATE_LB_USB_0_U20_PHY_REF_CLK_EN>,
						<&scmi_clk GATE_LB_USB_0_U31_PHY_REF_CLK_EN>,
						<&scmi_clk GATE_LB_USB_0_REF_ALT_CLK_EN>,
						<&scmi_clk GATE_LB_USB_0_AXI_ACLK_EN>,
						<&scmi_clk GATE_LB_USB_0_APB_PCLK_EN>;
			resets = <&scmi_reset RST_USB3_0_SW>;
			reset-names = "usb3_reset";
			phys = <&usb3_phy>;
			phy-names = "usb-phy";
			usbdwc3: dwc3@22000000 {
				compatible = "snps,dwc3";
				reg-shift = <2>;
				reg-io-width = <4>;
				reg = <0x0 0x22000000 0x0 0x100000>;
				interrupts = <0x0 172 0x4>;
				interrupt-parent =<&gic600>;
				dr_mode = "otg";
				usb-role-switch;
				role-switch-default-mode ="peripheral";
				maximum-speed = "super-speed";
				snps,ss_gen1_deemph = <1>;
				snps,ssp_gen2_deemph = <0x8c45>,<0xE45>,<0x8d80>,<0xf80>;
				//snps,dis_u3_susphy_quirk; //lane switch must through U3 state
				//snps,dis-u1-entry-quirk;
				//snps,dis-u2-entry-quirk;
				snps,hsphy_interface = "utmi";
				phy_type = "utmi_wide";
				//iommus = <&mmu600_soc 1>;
			};
		};

		dwc3: usb2 {
			compatible = "bst,dwc3usb";
			status = "disable";
			ranges;
			#address-cells = <2>;
			#size-cells = <2>;
			clock-names = "u2phyref","ref", "ctrlref", "axi", "apb";
			clocks = <&scmi_clk GATE_LB_USB_1_U20_PHY_REF_CLK_EN>,
						<&scmi_clk GATE_LB_USB_1_U31_PHY_REF_CLK_EN>,
						<&scmi_clk GATE_LB_USB_1_REF_ALT_CLK_EN>,
						<&scmi_clk GATE_LB_USB_1_AXI_ACLK_EN>,
						<&scmi_clk GATE_LB_USB_1_APB_PCLK_EN>;
			reset-names = "usb2_reset";
			resets = <&scmi_reset RST_USB3_1_SW>;
			phys = <&usb2_phy>;
			phy-names = "usb-phy";
			usbdwc2: dwc3@22100000 {
				compatible = "snps,dwc3";
				reg = <0x0 0x22100000 0x0 0x100000>;
				interrupts = <0x0 178 0x4>;
				interrupt-parent = <&gic600>;
				dr_mode = "otg";
				usb-role-switch;
				role-switch-default-mode ="host";
				maximum-speed = "super-speed";
				snps,ss_gen1_deemph = <1>;
				snps,ssp_gen2_deemph = <0x8c45>,<0xE45>,<0x8d80>,<0xf80>;
				//snps,dis_u3_susphy_quirk; //lane switch must through U3 state
				//snps,dis-u1-entry-quirk;
				//snps,dis-u2-entry-quirk;
				snps,hsphy_interface = "utmi";
				phy_type = "utmi_wide";
				//iommus = <&mmu600_soc 2>;
			};
		};
		bst_usb_msg: usb_msg@0 {
			compatible = "bst,bst-virt-usb";
			status = "okay";
        };


		nor_flash:flash {
			compatible = "bst,virtual-qspi";
			status = "disable";
		};


        timer0:lsp_timer0@20011000 {
			status = "disable";
			#address-cells = <1>;
			#size-cells = <0>;
            compatible = "bst,bst-lsp-timer"; 
            reg = <0x0 0x20011000 0 0x1000>;                      
            interrupt-parent = <&gic600>;                     
        };

        timer1:lsp_timer1@20031000 {
			status = "disable";
			#address-cells = <1>;
			#size-cells = <0>;
            compatible = "bst,bst-lsp-timer"; 
            reg = <0x0 0x20031000 0 0x1000>;                      
            interrupt-parent = <&gic600>;                     
        };

		mmc0:dwmmc0@22200000 {
			status = "okay";
			compatible = "bst,dwcmshc-sdhci";
			reg-name = "base","crm";
			reg = <0x0 0x22200000 0x0 0x1000>,
				  <0x0 0x23006000 0x0 0x1000>;
			port = <0>;
			interrupt-parent = <&gic600>;
			interrupts = <GIC_SPI 144 IRQ_TYPE_LEVEL_HIGH>;		//soc to db 110+32
			interrupt-names =  "IRQDWMMC0";
			#address-cells = <2>;
			#size-cells = <0>;


			clocks = <&scmi_clk GATE_LB_SDEMMC0_M_HCLK_EN>, <&scmi_clk GATE_LB_SDEMMC0_W_BCLK_EN>;
			clock-names = "core","bus";

			resets = <&scmi_reset RST_SDEMMC0_SW>;
			reset-names = "mmc_reset";



			clock-frequency = <200000000>;
			max-frequency = <200000000>;
			min-frequency = <400000>;
			mmc_crm_reg_base = <0x23006000>;
			data-addr = <0x200>;
			fifo-watermark-aligned;
			broken-64bit-dma;
			clear-tarns-mode;
			fifo-depth = <0x400>;
			card-detect-delay = <200>;
			//broken-adma;
			bus-width = <8>;
			#cap-mmc-highspeed;
			mmc-hs200-1_8v;
			non-removable;
			no-sdio;
			no-sd;
			keep-power-in-suspend;
			no-3-3-v;
			sdhci,auto-cmd12;
			dma-coherent;
			//iommus = <&mmu600_soc 8>;  //when use this, comment out memory-region attr
		};


		mmc1:dwmmc1@22300000 {
			status = "disable";
			compatible = "bst,dwcmshc-sdhci";
			reg = <0 0x22300000 0 0x1000>,
				  <0x0 0x23007000 0x0 0x1000>;
			port = <1>;
			interrupt-parent = <&gic600>;
			interrupts = <GIC_SPI 147 (GIC_CPU_MASK_SIMPLE(4) | IRQ_TYPE_LEVEL_HIGH)>;
			interrupt-names =  "IRQDWMMC1";
			#address-cells = <1>;
			#size-cells = <0>;
			data-addr = <0x200>;
			fifo-watermark-aligned;
			
			clocks = <&scmi_clk GATE_LB_SDEMMC1_M_HCLK_EN>, <&scmi_clk GATE_LB_SDEMMC1_W_BCLK_EN>;
			clock-names = "core","bus";		

			resets = <&scmi_reset RST_SDEMMC1_SW>;
			reset-names = "mmc_reset";


			clock-frequency = <100000000>;
			max-frequency = <200000000>;
			min-frequency = <400000>;
			mmc_crm_reg_base = <0x23007000>;
			broken-64bit-dma;
			broken-adma;
			clear-tarns-mode;
			fifo-depth = <0x400>;
			card-detect-delay = <200>;
			bus-width = <4>;
			cap-sd-highspeed;
			cap-uhs-sdr50;
			no-sdio;
			no-mmc;
			//no-1-8-v;
			sdhci,auto-cmd12;
			keep-power-in-suspend;
			dma-coherent;
		};

		mmu600_pcie: iommu@22800000 {
			status = "disable";
			compatible = "arm,smmu-v3";
			reg = <0x0 0x22800000 0x0 0x200000>;
			interrupt-parent = <&gic600>;
			interrupts = <GIC_SPI 95 IRQ_TYPE_LEVEL_HIGH>;
			interrupt-names = "combined";
			#iommu-cells = <1>;
			#cmn_dev_offset  = <0>;	// dev-->ddr: 1 :offset 0x10--, 0 :offset 0
			#cmn_tcu_offset = <0>;	// tcu-->ddr: 1 :offset 0x10--, 0 :offset 0
		};

		mmu600_codec: iommu@24400000 {
			status = "disable";
			compatible = "arm,smmu-v3";
			reg = <0x0 0x24400000 0 0x200000>;
			interrupt-parent = <&gic600>;
			interrupts = <GIC_SPI 281 IRQ_TYPE_LEVEL_HIGH>;    // non-secure irq
			interrupt-names = "combined";
			#iommu-cells = <1>;
			#cmn_dev_offset  = <1>; // dev-->ddr: 1 :offset 0x10--, 0 :offset 0
			#cmn_tcu_offset = <1>;  // tcu-->ddr: 1 :offset 0x10--, 0 :offset 0
		};

		mmu600_soc: iommu@31400000 {
			status = "disable";
			compatible = "arm,smmu-v3";
			reg = <0x0 0x31400000 0 0x200000>;
			interrupt-parent = <&gic600>;
			interrupts = <GIC_SPI 129 IRQ_TYPE_LEVEL_HIGH>;    // non-secure irq
			interrupt-names = "combined";
			#iommu-cells = <1>;
			#cmn_dev_offset  = <1>;	// dev-->ddr: 1 :offset 0x10--, 0 :offset 0
			#cmn_tcu_offset = <1>;	// tcu-->ddr: 1 :offset 0x10--, 0 :offset 0
			#multi_os = <1>;	// multi_os: 1 :shared use of multiple systems , 0 :single system use
		};

		mmu600_coreip: iommu@53600000 {
			status = "disable";
			compatible = "arm,smmu-v3";
			reg = <0x0 0x53600000 0 0x200000>;
			interrupt-parent = <&gic600>;
			interrupts = <GIC_SPI 374 IRQ_TYPE_LEVEL_HIGH>; // non-secure irq
			interrupt-names = "combined";
			#iommu-cells = <1>;
			#cmn_dev_offset = <0>; // dev-->ddr: 1 :offset 0x10--, 0 :offset 0
			#cmn_tcu_offset = <1>; // tcu-->ddr: 1 :offset 0x10--, 0 :offset 0
			#stage2 = <1>; // stage2 only: 1 :stage2, 0 :stage1
			#multi_os = <1>;
		};

		// mmu600_gpu: iommu@26400000

		ufs: ufs@23005000 {
			status = "disable";
			#address-cells = <1>;
			#size-cells = <0>;
			compatible = "snps,g210-tc-6.00-40bit";
			reg = <0x0 0x23005f00 0 0x100>,
			      <0x0 0x20031000 0 0x1000>;
			interrupt-parent = <&gic600>;
			interrupts = <GIC_SPI 81 IRQ_TYPE_LEVEL_HIGH>;
			lanes-per-direction = <2>;
//			iommus = <&mmu600_soc 3>;
		};

		// sd_csr apb 2300:6000

		pcie_phy:pcie-phy@23010000 {
			reg = <0x0 0x23010000 0 0x00002000>;
			reg-names = "phy-base";
			dmc-lane = <0x1>; /* bit0: 1=2x2ports, 0=1x4ports */
			dmc-mode = <0x3>; /* (bit1 for ctl0)/(bit0 for ctl1):1=RC-mode, 0=EP-mode */
			pcie-ctl0 = <1>;  /* Controller reset */
			pcie-ctl1 = <1>;  /* Controller reset */
			pcie-ref-clk0 = <1>; /* 0=onchip_clk, 1=pad_clk*/
			pcie-ref-clk1 = <1>; /* 0=onchip_clk, 1=pad_clk, 2=repeat_clk */
		};

		pcie0:pcie@400000000 {
			status = "disable";
			compatible = "bst,dw-pcie";
			device_type = "pci";
			controller-id = <0>;
			chip-type = <0x1>; /* 0x0=A1000 0x1=C1200 */
			bus-range = <0x0 0xf>;
			linux,pci-domain = <0>;
			max-link-speed = <4>;
			num-lanes = <4>;
			reg =	<0x4 0x00000000 0 0x00010000>,
				<0x5 0x80000000 0 0x00040000>,
				<0x5 0x80080000 0 0x00040000>,
				<0x0 0x40000000 0 0x00040000>;
			reg-names = "dbi", "atu", "dma", "config";
			num-ib-windows = <16>;
			num-ob-windows = <16>;
			msi-map = <0x0 &its0_x4 0x0 0x1000>;
			#address-cells = <3>;
			#size-cells = <2>;
			ranges = <0x82000000 0x0 0x40000000 0x4 0x20000000 0x0 0x80000000>,
				 <0x83000000 0x5 0x00000000 0x5 0x00000000 0x0 0x80000000>,
				 <0xC3000000 0x5 0x90000000 0x5 0x90000000 0x0 0x70000000>;
			dma-coherent;
			// iommus = <&mmu600_pcie 0x0>;
			// iommu-map = <0x0  &mmu600_pcie 0x00 0x1000>;

			interrupt-parent = <&gic600>;
			interrupts =	<GIC_SPI 65 IRQ_TYPE_LEVEL_HIGH>,
					<GIC_SPI 66 IRQ_TYPE_LEVEL_HIGH>,
					<GIC_SPI 55 IRQ_TYPE_LEVEL_HIGH>,
					<GIC_SPI 56 IRQ_TYPE_LEVEL_HIGH>,
					<GIC_SPI 57 IRQ_TYPE_LEVEL_HIGH>,
					<GIC_SPI 58 IRQ_TYPE_LEVEL_HIGH>,
					<GIC_SPI 59 IRQ_TYPE_LEVEL_HIGH>,
					<GIC_SPI 60 IRQ_TYPE_LEVEL_HIGH>,
					<GIC_SPI 61 IRQ_TYPE_LEVEL_HIGH>,
					<GIC_SPI 62 IRQ_TYPE_LEVEL_HIGH>;

			interrupt-names = "msi", "other", "dma0", "dma1", "dma2", "dma3", "dma4", "dma5", "dma6", "dma7";
			#interrupt-cells = <1>;
			interrupt-map-mask = <0 0 0 0x7>;
			interrupt-map = <0 0 0 1 &pcie0_intc 0xF>,
					<0 0 0 2 &pcie0_intc 0xE>,
					<0 0 0 3 &pcie0_intc 0xD>,
					<0 0 0 4 &pcie0_intc 0xC>;
			pcie-phy = <&pcie_phy>;

			pcie0_intc: legacy-interrupt-controller {
				interrupt-controller;
				#address-cells = <0>;
				#interrupt-cells = <1>;
				interrupt-parent = <&gic600>;
				interrupts = <GIC_SPI 66 IRQ_TYPE_LEVEL_HIGH>;
			};
		};

		pcie0_ep:pcie0_ep@400000000 {
			status = "disable";
			compatible = "bst,dw-pcie-ep";
			controller-id = <0>;
			chip-type = <0x1>; /* 0x0=A1000 0x1=C1200 */
			max-link-speed = <4>;
			num-lanes = <2>;
			reg =	<0x4 0x00000000 0 0x40000000>,
				<0x4 0x80000000 0 0x40000000>,
				<0x5 0x80000000 0 0x00040000>,
				<0x5 0x80080000 0 0x00040000>,
				<0x0 0x40000000 0 0x80000000>;
			reg-names = "dbi", "dbi2", "atu", "dma", "addr_space";
			dma-coherent;
			num-ib-windows = <16>;
			num-ob-windows = <16>;
			max-functions = /bits/ 8 <8>;
			max-virtual-functions = /bits/ 8 <4 4 0 0 0 0 0 0>;
			interrupt-parent = <&gic600>;
			interrupts =	<GIC_SPI 72 IRQ_TYPE_LEVEL_HIGH>,
					<GIC_SPI 55 IRQ_TYPE_LEVEL_HIGH>,
					<GIC_SPI 56 IRQ_TYPE_LEVEL_HIGH>,
					<GIC_SPI 57 IRQ_TYPE_LEVEL_HIGH>,
					<GIC_SPI 58 IRQ_TYPE_LEVEL_HIGH>,
					<GIC_SPI 59 IRQ_TYPE_LEVEL_HIGH>,
					<GIC_SPI 60 IRQ_TYPE_LEVEL_HIGH>,
					<GIC_SPI 61 IRQ_TYPE_LEVEL_HIGH>,
					<GIC_SPI 62 IRQ_TYPE_LEVEL_HIGH>;
			interrupt-names = "doorbell", "dma0", "dma1", "dma2", "dma3", "dma4", "dma5", "dma6", "dma7";

			pcie-phy = <&pcie_phy>;
		};

		pcie1:pcie@600000000 {
			status = "disable";
			compatible = "bst,dw-pcie";
			device_type = "pci";
			controller-id = <1>;
			chip-type = <0x1>; /* 0x0=A1000 0x1=C1200 */
			bus-range = <0x10 0x1f>;
			linux,pci-domain = <1>;
			max-link-speed = <4>;
			num-lanes = <2>;
			reg =	<0x6 0x00000000 0 0x00010000>,
				<0x7 0x80000000 0 0x00040000>,
				<0x7 0x80080000 0 0x00040000>,
				<0x0 0x48000000 0 0x00040000>;
			reg-names = "dbi", "atu", "dma", "config";
			num-iatu = <16>;
			num-viewport = <16>;
			msi-map = <0x1000 &its1_x2 0x1000 0x1000>;
			#address-cells = <3>;
			#size-cells = <2>;
			ranges = <0x82000000 0x0 0x60000000 0x6 0x20000000 0x0 0x80000000>,
				 <0x83000000 0x7 0x00000000 0x7 0x00000000 0x0 0x80000000>,
				 <0xC3000000 0x7 0x90000000 0x7 0x90000000 0x0 0x70000000>;
			dma-coherent;
			// iommus = <&mmu600_pcie 0x1000>;
			// iommu-map = <0x1000  &mmu600_pcie 0x1000 0x1000>;

			interrupt-parent = <&gic600>;
			interrupts =	<GIC_SPI 92 IRQ_TYPE_LEVEL_HIGH>,
					<GIC_SPI 84 IRQ_TYPE_LEVEL_HIGH>,
					<GIC_SPI 74 IRQ_TYPE_LEVEL_HIGH>,
					<GIC_SPI 75 IRQ_TYPE_LEVEL_HIGH>,
					<GIC_SPI 76 IRQ_TYPE_LEVEL_HIGH>,
					<GIC_SPI 77 IRQ_TYPE_LEVEL_HIGH>,
					<GIC_SPI 78 IRQ_TYPE_LEVEL_HIGH>,
					<GIC_SPI 79 IRQ_TYPE_LEVEL_HIGH>,
					<GIC_SPI 80 IRQ_TYPE_LEVEL_HIGH>,
					<GIC_SPI 81 IRQ_TYPE_LEVEL_HIGH>;
			interrupt-names = "msi", "other", "dma0", "dma1", "dma2", "dma3", "dma4", "dma5", "dma6", "dma7";
			#interrupt-cells = <1>;
			interrupt-map-mask = <0 0 0 0x7>;
			interrupt-map = <0 0 0 1 &pcie1_intc 0xF>,
					<0 0 0 2 &pcie1_intc 0xE>,
					<0 0 0 3 &pcie1_intc 0xD>,
					<0 0 0 4 &pcie1_intc 0xC>;
			pcie-phy = <&pcie_phy>;

			pcie1_intc: legacy-interrupt-controller {
				interrupt-controller;
				#address-cells = <0>;
				#interrupt-cells = <1>;
				interrupt-parent = <&gic600>;
				interrupts = <GIC_SPI 84 IRQ_TYPE_LEVEL_HIGH>;
			};
		};

		pcie1_ep:pcie1_ep@600000000 {
			status = "disable";
			compatible = "bst,dw-pcie-ep";
			controller-id = <1>;
			chip-type = <0x1>; /* 0x0=A1000 0x1=C1200 */
			reg =	<0x6 0x00000000 0 0x40000000>,
				<0x6 0x80000000 0 0x40000000>,
				<0x7 0x80000000 0 0x00040000>,
				<0x7 0x80080000 0 0x00040000>,
				<0x0 0x48000000 0 0x80000000>;
			reg-names = "dbi", "dbi2", "atu", "dma", "addr_space";
			dma-coherent;
			num-ib-windows = <16>;
			num-ob-windows = <16>;
			max-functions = /bits/ 8 <8>;
			max-virtual-functions = /bits/ 8 <4 4 0 0 0 0 0 0>;
			interrupt-parent = <&gic600>;
			interrupts =	<GIC_SPI 90 IRQ_TYPE_LEVEL_HIGH>,
					<GIC_SPI 74 IRQ_TYPE_LEVEL_HIGH>,
					<GIC_SPI 75 IRQ_TYPE_LEVEL_HIGH>,
					<GIC_SPI 76 IRQ_TYPE_LEVEL_HIGH>,
					<GIC_SPI 77 IRQ_TYPE_LEVEL_HIGH>,
					<GIC_SPI 78 IRQ_TYPE_LEVEL_HIGH>,
					<GIC_SPI 79 IRQ_TYPE_LEVEL_HIGH>,
					<GIC_SPI 80 IRQ_TYPE_LEVEL_HIGH>,
					<GIC_SPI 81 IRQ_TYPE_LEVEL_HIGH>;
			interrupt-names = "doorbell", "dma0", "dma1", "dma2", "dma3", "dma4", "dma5", "dma6", "dma7";

			pcie-phy = <&pcie_phy>;
		};

		// Media_system
		codec0:linlon-v5@0x24200000 {
			status = "disable";
			compatible = "arm china,linlon-v5";
			reg = <0 0x24200400 0 0x10000>;
			interrupt-parent = <&gic600>;
			interrupts = <0 276 4>;
		};

		codec1:linlon-v5@0x24300000 {
			status = "disable";
			compatible = "arm china,linlon-v5";
			reg = <0 0x24300400 0 0x10000>;
			interrupt-parent = <&gic600>;
			interrupts = <0 277 4>;
		};

		xrp0: xrp@0{
			#address-cells = <1>;
			#size-cells = <1>;
			compatible = "bst,xrp-hw-simple,v1";
			status = "okay";
			reg = <0x8 0x6400000 0x0 0x100000>,  /* shared mem*/
				<0x0 0x24d00000 0x0 0x00000200>; /* DSP MMIO */
			device-irq = <0 1 5>; /* offset, bit#, IRQ# */
			device-irq-host-offset = <0>;
			device-irq-mode = <0>;
			dma-coherent; /* smmu mask */
//			memory-region = <&bst_sramxrp_reserved>;
			host-irq = <0xfffff000 0>; /* offset, bit# */
			host-irq-mode = <0>;
			interrupt-parent = <&gic600>;
			interrupts = <GIC_SPI 141 IRQ_TYPE_LEVEL_HIGH>;
			firmware-name = "xrp0";
			ranges = < 0x80000000 0x0 0x80000000 0x500000>,
					<0x86400000 0x8 0x6400000 0x100000>,
					<0xA4ac0000 0x0 0x24ac0000 0x20000>,
					<0xA4ae0000 0x0 0x24ae0000 0x20000>;
			dsp@0 {
			};
		};

		vmac_hif_rx_setup: vmac-rx-queues-config {
			rx-queues-to-use = <1>;
		};

		vmac_hif_tx_setup: vmac-tx-queues-config {
			tx-queues-to-use = <1>;
		};

		vmac: ethernet@0x35000000 {
			status = "disable";
			compatible = "bst,vmac-hif";
			reg = <0x0 0x35000000 0 0xffffff>;
			hif-rx-config = <&vmac_hif_rx_setup>;
			hif-tx-config = <&vmac_hif_tx_setup>;
			ethernet-id = <0>;
		};
//************************Mipi CSITX Start *********************************************/

        csi_tx: csi_tx@0x24600000 {
                status = "disable";
                compatible = "bst,c1200_csi_tx";
                reg = <0x0 0x24600000 0 0x1000>,  //csi device
                      <0x0 0x24e01000 0 0x1000>,  //switch
                      <0x0 0x2460c000 0 0x4000>,  //dphy
                      <0x0 0x24e00000 0 0x1000>;  //media_dma
                lane-speed = <2500>;
                lane-num = <4>;
                vc-num = <4>;
		clocks= <&scmi_clk GATE_LB_MEDIA_DMA_ACLK_EN>, <&scmi_clk GATE_LB_MEDIA_DMA_HCLK_EN>;
		clock-names = "aclk","hclk";
		resets = <&scmi_reset RST_MEDIA_DMA_SW>;
		reset-names = "media_dma";
                interrupt-parent = <&gic600>;
                interrupts = <GIC_SPI 298 IRQ_TYPE_LEVEL_HIGH>;
                interrupt-names = "csi_dma";
        };

//************************Mipi CSITX End*********************************************/

		// ************************Native Display *********************************************/
		bst_dpu2:display@0x29000000 {
			status = "disable";
			compatible = "bst,c1200-native-display2";
			reg = <0x0 0x29000000 0 0x800000>,  // for C1200 Display2
				  <0x0 0x24F00000 0 0x100>,
				  <0x0 0x30230000 0 0x10000>;
			reg-names = "dpu-base","csr-base", "mdnoc-qos-base";
			interrupt-parent = <&gic600>;
			interrupts = <GIC_SPI 291 IRQ_TYPE_LEVEL_HIGH>;
			#address-cells = <1>;
			#size-cells = <0>;
			assigned-clocks = <&scmi_clk PLL_DISPLAY_MUX4_1188_CLK_SEL >;
			assigned-clock-parents = <&scmi_clk CLK3_1188>;
			pipeline@0 {
				reg = <0>;
				clocks= <&scmi_clk PLL_CLK_DISPLAY3>,<&scmi_clk DIVIDOR_DISPLAY2_CH0>,<&scmi_clk GATE_LB_DISPLAY2_CH0_CLK_EN>,<&scmi_clk GATE_LB_DISPLAY2_ACLK_EN >,<&scmi_clk GATE_LB_DISPLAY2_PCLK_EN>,<&scmi_clk MUX_DISPLAY2_ACLK_SEL>;
				clock-names = "pll_clk","div_clk","gate_pixelclk","gate_aclk","gate_pclk","mux_aclk";

				port {
					#address-cells = <1>;
					#size-cells = <0>;
					dpu2_pipe0_link0_out: endpoint@0 {
						reg = <0>;
						remote-endpoint = <&bst_dptx_host>;
					};
				};
			};
		};

		bst_dpu1:display@0x28800000 {
			status = "disable";
			compatible = "bst,c1200-native-display1";
			reg = <0x0 0x28800000 0 0x800000>,  // for C1200 Display1
				  <0x0 0x24F00000 0 0x100>,
				  <0x0 0x30230000 0 0x10000>;
			reg-names = "dpu-base","csr-base", "mdnoc-qos-base";
			interrupt-parent = <&gic600>;
			interrupts = <GIC_SPI 285 IRQ_TYPE_LEVEL_HIGH>;
			#address-cells = <1>;
			#size-cells = <0>;
			assigned-clocks = <&scmi_clk PLL_DISPLAY_MUX2_1188_CLK_SEL >,<&scmi_clk PLL_DISPLAY_MUX3_1188_CLK_SEL >;
			assigned-clock-parents = <&scmi_clk CLK2_1188>,<&scmi_clk CLK2_1188>;
			pipeline@0 {
				reg = <0>;
				clocks= <&scmi_clk PLL_CLK_DISPLAY2>,<&scmi_clk DIVIDOR_DISPLAY1_CH0>,<&scmi_clk GATE_LB_DISPLAY1_CH0_CLK_EN>,<&scmi_clk GATE_LB_DISPLAY1_ACLK_EN >,<&scmi_clk GATE_LB_DISPLAY1_PCLK_EN>,<&scmi_clk MUX_DISPLAY1_ACLK_SEL>;
				clock-names = "pll_clk","div_clk","gate_pixelclk","gate_aclk","gate_pclk","mux_aclk";
				port {
					#address-cells = <1>;
					#size-cells = <0>;
					dpu1_pipe0_link0_out: endpoint@0 {
						reg = <0>;
						//remote-endpoint = <&bst_lvds_ch1_in>;
						remote-endpoint = <&bst_dsi1_host_in>;
					};
				};
			};
			pipeline@1 {
				reg = <1>;
				clocks= <&scmi_clk PLL_CLK_DISPLAY2>,<&scmi_clk DIVIDOR_DISPLAY1_CH1>,<&scmi_clk GATE_LB_DISPLAY1_CH1_CLK_EN>,<&scmi_clk GATE_LB_DISPLAY1_ACLK_EN >,<&scmi_clk GATE_LB_DISPLAY1_PCLK_EN>,<&scmi_clk MUX_DISPLAY1_ACLK_SEL>;
				clock-names = "pll_clk","div_clk","gate_pixelclk","gate_aclk","gate_pclk","mux_aclk";

				port {
					#address-cells = <1>;
					#size-cells = <0>;
					dpu1_pipe1_link0_out: endpoint@0 {
						reg = <0>;
						//remote-endpoint = <&bst_lvds_ch2_in>;
						remote-endpoint = <&bst_dsi0_host_in>;
					};
				};
			};
		};

		bst_dpu0:display@0x28000000  {
			compatible = "bst,c1200-native-display0";
			status = "disable";
			reg = <0x0 0x28000000 0 0x800000>,  // for C1200 Display0
				  <0x0 0x24F00000 0 0x100>,
				  <0x0 0x30230000 0 0x10000>;
			reg-names = "dpu-base","csr-base", "mdnoc-qos-base";
			interrupt-parent = <&gic600>;
			#address-cells = <1>;
			#size-cells = <0>;
			interrupts = <GIC_SPI 283 IRQ_TYPE_LEVEL_HIGH>;
			assigned-clocks = <&scmi_clk PLL_DISPLAY_MUX0_1188_CLK_SEL >,<&scmi_clk PLL_DISPLAY_MUX1_1188_CLK_SEL>;
			assigned-clock-parents = <&scmi_clk CLK0_1188>,<&scmi_clk CLK1_1188>;
			pipeline@0 {
				reg = <0>;
				clocks= <&scmi_clk PLL_CLK_DISPLAY0>,<&scmi_clk DIVIDOR_DISPLAY0_CH0>,<&scmi_clk GATE_LB_DISPLAY0_CH0_CLK_EN>,<&scmi_clk GATE_LB_DISPLAY0_ACLK_EN >,<&scmi_clk GATE_LB_DISPLAY0_PCLK_EN >,<&scmi_clk MUX_DISPLAY0_ACLK_SEL >;
				clock-names = "pll_clk","div_clk","gate_pixelclk","gate_aclk","gate_pclk","mux_aclk";
				port {
					#address-cells = <1>;
					#size-cells = <0>;
					dpu0_pipe0_link0_out: endpoint@0 {
						reg = <0>;
						remote-endpoint = <&bst_lvds_ch1_in>;
					};
				};
			};
			pipeline@1 {
				reg = <1>;
				clocks= <&scmi_clk PLL_CLK_DISPLAY1>,<&scmi_clk DIVIDOR_DISPLAY0_CH1>,<&scmi_clk GATE_LB_DISPLAY0_CH1_CLK_EN>,<&scmi_clk GATE_LB_DISPLAY0_ACLK_EN >,<&scmi_clk GATE_LB_DISPLAY0_PCLK_EN >,<&scmi_clk MUX_DISPLAY0_ACLK_SEL >;
				clock-names = "pll_clk","div_clk","gate_pixelclk","gate_aclk","gate_pclk","mux_aclk";
				port {
					#address-cells = <1>;
					#size-cells = <0>;
					dpu0_pipe1_link0_out: endpoint@0 {
						reg = <0>;
						// remote-endpoint = <&bst_vout_panel>;
					};
				};
			};
		};

		/* for VOUT_CONN EVM hardware version */
		vout_conn:vout_connector@0 {
			status = "okay";
			compatible = "bst,bst-vout-conn";
			#address-cells = <1>;
			#size-cells = <0>;
			reg = <0x0 0x24F00000 0x0 0x1000>;
			display-timings {
				timing_1920x1080p60 {
					clock-frequency = <148500000>;
					hactive = <1920>;
					vactive = <1080>;
					hsync-len = <0 44 60>;
					hfront-porch = <80 88 95>;
					hback-porch = <100 148 160>;
					vfront-porch = <0 4 6>;
					vback-porch = <0 36 50>;
					vsync-len = <0 5 6>;
				};
				timing_3840x2160p30 {
					clock-frequency = <297000000>;
					hactive = <3840>;
					vactive = <2160>;
					hsync-len = <0 88 120>;
					hfront-porch = <160 176 190>;
					hback-porch = <200 296 320>;
					vfront-porch = <0 8 12>;
					vback-porch = <0 72 100>;
					vsync-len = <0 10 12>;
				};
			};
			ports {
				#address-cells = <1>;
				#size-cells = <0>;
				port@0 {
					reg = <0>;
					bst_vout_panel: endpoint@0 {
						// remote-endpoint = <&dpu0_pipe1_link0_out>;
					};
				};
			};
		};


		bst-lvds-panel0 {
			compatible = "panel-lvds";
			rotation = <0>;
			label = "lvdspanel0";
			data-mapping = "vesa-24";//vesa-24 jeida-24
			width-mm = <1920>;
			height-mm = <720>;
			panel-timing {
				clock-frequency = <93600000>;
				hactive = <1920>;
				vactive = <720>;
				hfront-porch = <70>;
				hback-porch = <47>;
				hsync-len = <43>;
				vsync-len = <3>;
				vfront-porch = <3>;
				vback-porch = <24>;
				vsync-active = <0>;
				hsync-active = <0>;
			};
			port {
				lvds_panel:endpoint@0 {
					remote-endpoint = <&bst_lvds_ch1_out>;
				};
			};
		};

		bst-lvds-panel1 {
			compatible = "bst,lvds1-panel";
			rotation = <0>;
			label = "lvdspanel1";
			data-mapping = "vesa-24";//vesa-24 jeida-24
			width-mm = <1920>;
			height-mm = <720>;
			panel-timing {
				clock-frequency = <93600000>;
				hactive = <1920>;
				vactive = <720>;
				hfront-porch = <70>;
				hback-porch = <47>;
				hsync-len = <43>;
				vsync-len = <3>;
				vfront-porch = <3>;
				vback-porch = <24>;
				vsync-active = <0>;
				hsync-active = <0>;
			};
			port {
				lvds_panel1:endpoint@1 {
					remote-endpoint = <&bst_lvds_ch2_out>;
				};
			};
		};

		lvds_conn:lvds_conn@0x24F01000 {
			status = "disable";
			compatible = "bst,bst-lvds-conn";
			#address-cells = <1>;
			#size-cells = <0>;
			reg = <0x0 0x24F01000 0x0 0x1000>;
			assigned-clocks = <&scmi_clk CLK_LVDS0_HSPEED_1188 >,<&scmi_clk CLK_LVDS1_HSPEED_1188 >;
			assigned-clock-parents = <&scmi_clk CLK0_1188>,<&scmi_clk CLK1_1188>;
			lvds_channel@0{
				output = <1>;   /*0 invalid,1 o_channel,2 e_channel,3 dualchannel,lvds0 and lvds1 cannot select the same output channel*/
				data-mapping = "vesa-24";
				reg = <0>;
				ports {
				#address-cells = <1>;
				#size-cells = <0>;
					port@0 {
						reg = <0>;
						#address-cells = <1>;
						#size-cells = <0>;
						bst_lvds_ch1_out: endpoint@0 {
							reg = <0>;
							remote-endpoint = <&lvds_panel>;
						};
					};
					port@1 {
						reg = <1>;
						#address-cells = <1>;
						#size-cells = <0>;
						bst_lvds_ch1_in: endpoint@0 {
							reg = <0>;
							remote-endpoint = <&dpu0_pipe0_link0_out>;
						};
					};
				};
			};

			lvds_channel@1{
				output = <2>;//0 invalid,1 o_channel,2 e_channel,3 dualchannel,lvds0 and lvds1 cannot select the same output channel
				data-mapping = "vesa-24";
				reg = <1>;
				ports {
					#address-cells = <1>;
					#size-cells = <0>;
					port@0 {
						reg = <0>;
						bst_lvds_ch2_out: endpoint@0 {
							remote-endpoint = <&lvds_panel1>;
						};
					};
					port@1 {
						reg = <1>;
						bst_lvds_ch2_in: endpoint@0 {
							// remote-endpoint = <&dpu0_pipe1_link0_out>;
						};
					};
				};
			};
		};

		mipi_dsi0:dsi0@0x24608000 {
				status = "disable";
				compatible = "bst,bst-dsi";
				#address-cells = <0x1>;
				#size-cells = <0x0>;
				reg = <0x0 0x24608000 0 0x4000>;
				reg-names = "dsi-base";
				//dual-link;
				clocks= <&scmi_clk GATE_LB_DSI_PCLK_EN>;
				clock-names = "pclk";
				ports {
					#address-cells = <1>;
					#size-cells = <0>;
					port@0 {
						reg = <0>;
						bst_dsi0_host_in: endpoint@0 {
							remote-endpoint = <&dpu1_pipe1_link0_out>;
						};
					};
					port@1{
						reg = <1>;
						bst_dsi_output:endpoint@1 {
							remote-endpoint = <&dsi_panel>;
						};
					};
				};
				mipi_panel: panel@0 {
					compatible = "bst,boe_1920x1080";
					reg = <0>;
					ports {
						#address-cells = <1>;
						#size-cells = <0>;
						port@0 {
							reg = <0>;
							dsi_panel: endpoint@0 {
								remote-endpoint = <&bst_dsi_output>;
							};
						};
					};
				};
		};
		mipi_dsi1:dsi1@0x24604000 {
			status = "disable";
			compatible = "bst,bst-dsi";
			#address-cells = <0x1>;
			#size-cells = <0x0>;
			reg =<0x0 0x24604000 0 0x4000>;
			reg-names = "dsi-base";
			clocks= <&scmi_clk GATE_LB_DSI_PCLK_EN>;
			clock-names = "pclk";
				ports {
					#address-cells = <1>;
					#size-cells = <0>;
					port@0 {
						reg = <0>;
						bst_dsi1_host_in: endpoint@0 {
							remote-endpoint = <&dpu1_pipe0_link0_out>;
						};
					};
					port@1{
						reg = <1>;
						bst_dsi1_output:endpoint@1 {
							remote-endpoint = <&dsi1_panel>;
						};
					};
				};
				mipi_panel1: panel@1 {
					compatible = "bst,panel_bst";
					reg = <1>;
					ports {
						#address-cells = <1>;
						#size-cells = <0>;
						port@1 {
							reg = <1>;
							dsi1_panel: endpoint@1 {
								remote-endpoint = <&bst_dsi1_output>;
							};
						};
					};
				};
		};
		mipi_csr: mipi_csr@0x2460c000 {
			status = "disable";
			compatible = "bst,bst-mipi-csr", "syscon";
			reg = <0x0 0x2460c000 0 0x4000>;
		};

		bst_dptx: dptx@24C30000 {
			status = "disable";
			compatible = "bst,bst-dptx";
			reg = <0x0 0x24C30000 0x0 0x10000>,	// EDP CORE
				  <0x0 0x24C10000 0x0 0x10000>,	// EDP CSR
				  <0x0 0x2002C000 0x0 0x1000>;	// SOC_LSP1 I2S3_out->eDP_in
			interrupt-parent = <&gic600>;
			interrupts = <GIC_SPI 300 IRQ_TYPE_LEVEL_HIGH>;
			/* lane-speed = 1620(RBR)/2700(HBR)/5400(HBR2)/8100(HBR3) */
			lane-speed = <5400>;    // 1620/2700/5400/8100
			lane-num = <4>;         // 1/2/4 lane(s)
			colorimetry = <1>;		// 1-ITU601, 2-ITU709
			dynamic-range = <1>;	// 1-CEA, 2-VESA
			video-bpc = <8>;        // 6/8/10/12/16 bit
			pixel-encode = <0>;	// 0-RGB,1-YCBCR420,2-YCBCR422,3-YCBCR444,4-YONLY,5-RAW
			dp-interface = <0>;     // 0-DP,1-eDP
			force-hpd = <1>;        // 0-no force,1-force
			ssc-enable = <0>;       // 0-disable, 1-enable
			bypass-training = <0>;  // 0-training,1-bypass training
			ports {
				#address-cells = <1>;
				#size-cells = <0>;
				dptx_in: port@0 {
					reg = <0>;
					bst_dptx_host: endpoint@0 {
						remote-endpoint = <&dpu2_pipe0_link0_out>;
					};
				};
				dptx_out: port@1 {
					reg = <1>;
					dptx_out_to_panel: endpoint@0 {
						remote-endpoint = <&dp_panel_in>;
					};
				};
			};
		};

		dp_panel:bst-dp-panel {
			compatible = "bst,dp-panel";
			status = "disable";
			rotation = <0>;
			no-hpd;
			// is_edp; /* edp panel type, need config dp-interface = <1> */
			panel-timing {
				/* 1920x1080 - Common*/
				// clock-frequency = <148500000>;
				// hactive = <1920>;
				// vactive = <1080>;
				// hfront-porch = <88>;
				// hback-porch = <148>;
				// hsync-len = <44>;
				// vsync-len = <5>;
				// vfront-porch = <4>;
				// vback-porch = <36>;
				// vsync-active = <0>;
				// hsync-active = <0>;

				/* 4032x756 - Bringup*/
				// clock-frequency = <198300000>;
				// hactive = <4032>;
				// vactive = <756>;
				// hfront-porch = <72>;
				// hback-porch = <72>;
				// hsync-len = <72>;
				// vsync-len = <2>;
				// vfront-porch = <12>;
				// vback-porch = <8>;
				// vsync-active = <0>;
				// hsync-active = <1>;

				/* 1920x720 - CES */
				// clock-frequency = <93600000>;
				// hactive = <1920>;
				// vactive = <720>;
				// hfront-porch = <70>;
				// hback-porch = <47>;
				// hsync-len = <43>;
				// vsync-len = <3>;
				// vfront-porch = <3>;
				// vback-porch = <24>;
				// vsync-active = <0>;
				// hsync-active = <0>;

				/* 3840x2160 - CES */
				// clock-frequency = <297000000>;
				// hactive = <3840>;
				// vactive = <2160>;
				// hfront-porch = <176>;
				// hback-porch = <296>;
				// hsync-len = <88>;
				// vsync-len = <10>;
				// vfront-porch = <8>;
				// vback-porch = <72>;
				// vsync-active = <1>;
				// hsync-active = <1>;

				/* 2560x1440@59.95hz */
				// clock-frequency = <241500000>;
				// hactive = <2560>;
				// vactive = <1440>;
				// hfront-porch = <48>;
				// hback-porch = <80>;
				// hsync-len = <32>;
				// vsync-len = <5>;
				// vfront-porch = <3>;
				// vback-porch = <33>;
				// vsync-active = <0>;
				// hsync-active = <1>;

				/* 4096x2160@60Hz */
				// clock-frequency = <594000000>;
				// hactive = <4096>;
				// vactive = <2160>;
				// hfront-porch = <88>;
				// hback-porch = <128>;
				// hsync-len = <88>;
				// vsync-len = <10>;
				// vfront-porch = <8>;
				// vback-porch = <72>;
				// vsync-active = <1>;
				// hsync-active = <1>;

				/* 1280x720@60Hz */
				// clock-frequency = <74250000>;
				// hactive = <1280>;
				// vactive = <720>;
				// hfront-porch = <110>;
				// hback-porch = <220>;
				// hsync-len = <40>;
				// vsync-len = <5>;
				// vfront-porch = <5>;
				// vback-porch = <20>;
				// vsync-active = <1>;
				// hsync-active = <1>;

				/* 2560x1080@60Hz */
				// clock-frequency = <198000000>;
				// hactive = <2560>;
				// vactive = <1080>;
				// hfront-porch = <248>;
				// hback-porch = <148>;
				// hsync-len = <44>;
				// vsync-len = <5>;
				// vfront-porch = <4>;
				// vback-porch = <11>;
				// vsync-active = <1>;
				// hsync-active = <1>;
			};
			port {
				dp_panel_in: endpoint@0 {
					remote-endpoint = <&dptx_out_to_panel>;
				};
			};
		};
//************************Native Display End*********************************************/

//************************Virtual Display Start******************************************/
		bst_disp_fw_msgbx: display_firmware@0 {
			compatible = "bst,bst-display-firmware-msgbx";
			status = "disable";
		};
		bst_disp_fw_ipc: display_firmware@1 {
			compatible = "bst,bst-display-firmware-ipc";
			status = "disable";
		};

		bst_virt_dpu0: bst_virt_dpu@0 {
			compatible = "bst,c1200-virtual-display0";
			status = "disable";
			#address-cells = <1>;
			#size-cells = <0>;
			os-type = "ADAS"; /* "ADAS", "DB", "IVI" */
			pipeline@0 {
				status = "disable";
				reg = <0>;
				layer-num = <4>;
				#address-cells = <1>;
				#size-cells = <0>;
				port@0 {
					#address-cells = <1>;
					#size-cells = <0>;
					virt_pipe0_out: endpoint@0 {
						reg = <0>;
						//remote-endpoint = <&virt_dptx_in>;
					};
				};
			};

			pipeline@1 {
				status = "disable";
				reg = <1>;
				layer-num = <2>;
				#address-cells = <1>;
				#size-cells = <0>;
				port@0 {
					reg = <0>;
					#address-cells = <1>;
					#size-cells = <0>;
					virt_pipe1_out: endpoint@0 {
						reg = <0>;
						//remote-endpoint = <&virt_dsi0_in>;
					};
				};
			};

			pipeline@2 {
				status = "disable";
				reg = <2>;
				layer-num = <1>;
				#address-cells = <1>;
				#size-cells = <0>;
				port@0 {
					reg = <0>;
					#address-cells = <1>;
					#size-cells = <0>;
					virt_pipe2_out: endpoint@0 {
						reg = <0>;
						//remote-endpoint = <&virt_dsi1_in>;
					};
				};
			};

			pipeline@3 {
				status = "disable";
				reg = <3>;
				layer-num = <1>;
				#address-cells = <1>;
				#size-cells = <0>;
				port@0 {
					reg = <0>;
					#address-cells = <1>;
					#size-cells = <0>;
					virt_pipe3_out: endpoint@0 {
						reg = <0>;
						//remote-endpoint = <&virt_lvds1_in>;
					};
				};
			};
			pipeline@4 {
				status = "disable";
				reg = <4>;
				layer-num = <1>;
				#address-cells = <1>;
				#size-cells = <0>;
				port@0 {
					reg = <0>;
					#address-cells = <1>;
					#size-cells = <0>;
					virt_pipe4_out: endpoint@0 {
						reg = <0>;
						//remote-endpoint = <&virt_lvds0_in>;
					};
				};
			};
		};

		bst_virt_dptx: bst-virt-conn@0 {
			compatible = "bst,virt-dp";
			status = "disable";
			#address-cells = <1>;
			#size-cells = <0>;
			ports {
				#address-cells = <1>;
				#size-cells = <0>;
				port@0 {
					reg = <0>;
					#address-cells = <1>;
					#size-cells = <0>;
					virt_dptx_in: endpoint@0 {
						reg = <0>;
						// remote-endpoint = <&virt_pipe0_out>;
					};
				};
			};
		};

		bst_virt_lvds0: bst-virt-conn@1 {
			compatible = "bst,virt-lvds0";
			status = "disable";
			ports {
				#address-cells = <0x01>;
				#size-cells = <0x00>;
				port@0 {
					reg = <0>;
					#address-cells = <1>;
					#size-cells = <0>;
					virt_lvds0_in: endpoint@0 {
						reg = <0>;
						//remote-endpoint = <&virt_pipe0_out>;
					};
				};
			};
		};

		bst_virt_lvds1: bst-virt-conn@2 {
			compatible = "bst,virt-lvds1";
			status = "disable";
			#address-cells = <1>;
			#size-cells = <0>;
			ports {
				#address-cells = <0x01>;
				#size-cells = <0x00>;
				port@0 {
					reg = <0>;
					#address-cells = <1>;
					#size-cells = <0>;
					virt_lvds1_in: endpoint@0 {
						reg = <0>;
						//remote-endpoint = <&virt_pipe3_out>;
					};
				};
			};
		};

		bst_virt_dsi0: bst-virt-conn@3 {
			compatible = "bst,virt-dsi0";
			status = "disable";
			#address-cells = <1>;
			#size-cells = <0>;
			ports {
				#address-cells = <1>;
				#size-cells = <0>;
				port@0 {
					reg = <0>;
					#address-cells = <1>;
					#size-cells = <0>;
					virt_dsi0_in: endpoint@0 {
						reg = <0>;
						//remote-endpoint = <&virt_pipe1_out>;
					};
				};
			};
		};
		bst_virt_dsi1: bst-virt-conn@4 {
			compatible = "bst,virt-dsi1";
			status = "disable";
			#address-cells = <1>;
			#size-cells = <0>;
			ports {
				#address-cells = <1>;
				#size-cells = <0>;
				port@0 {
					reg = <0>;
					#address-cells = <1>;
					#size-cells = <0>;
					virt_dsi1_in: endpoint@0 {
						reg = <0>;
						//remote-endpoint = <&virt_pipe2_out>;
					};
				};
			};
		};
//************************Virt Display End*********************************************/

		gpu_ivi:gpu@0x26100000 {
			status = "disable";
			compatible = "arm,mali-midgard";
			reg = < 0x0 0x26100000 0x0 0x4000>;
			interrupt-parent = <&gic600>;
			interrupts = <GIC_SPI 37 IRQ_TYPE_LEVEL_HIGH>, <GIC_SPI 37 IRQ_TYPE_LEVEL_HIGH>, <GIC_SPI 37 IRQ_TYPE_LEVEL_HIGH>;
			interrupt-names = "JOB", "MMU", "GPU";
			resets = <&scmi_reset RST_GPU_G78AE_SW>;
			reset-names = "g78ae_mp_reset";
			physical-memory-group-manager = <&gpu_physical_memory_group_manager>;
		};

		gpu_adas:gpu@0x260e0000 {
			status = "disable";
			compatible = "arm,mali-midgard";
			reg = < 0x0 0x260e0000 0x0 0x4000>;
			interrupt-parent = <&gic600>;
			interrupts = <GIC_SPI 36 IRQ_TYPE_LEVEL_HIGH>, <GIC_SPI 36 IRQ_TYPE_LEVEL_HIGH>, <GIC_SPI 36 IRQ_TYPE_LEVEL_HIGH>;
			interrupt-names = "JOB", "MMU", "GPU";
			resets = <&scmi_reset RST_GPU_G78AE_SW>;
			reset-names = "g78ae_mp_reset";
			physical-memory-group-manager = <&gpu_physical_memory_group_manager>;
		};

		gpu_db:gpu@0x344e0000 {
			status = "disable";
			compatible = "arm,mali-midgard";
			reg = <0x0 0x344e0000 0 0x4000>;
			interrupt-parent = <&gic600>;
			interrupts = <GIC_SPI 153 IRQ_TYPE_LEVEL_HIGH>, <GIC_SPI 153 IRQ_TYPE_LEVEL_HIGH>, <GIC_SPI 153 IRQ_TYPE_LEVEL_HIGH>;
			interrupt-names = "JOB", "MMU", "GPU";
			resets = <&scmi_reset RST_GPU_G78AE_SP_SW>;
			reset-names = "g78ae_sp_reset";
			physical-memory-group-manager = <&gpu_physical_memory_group_manager>;
		};

		gpu_physical_memory_group_manager: physical-memory-group-manager {
			compatible = "arm,physical-memory-group-manager";
		};

		gpu_dma_buf:dma_exporter@0 {
			compatible = "bst,g78_dma_buf";
		};

		// CFG_SOC_SYS
		// sysctrl 3000:0000

		pinctrl: pinctrl@30001000 {
			status = "disable";
			compatible = "bst,pinctrl-c1200";
			#address-cells = <2>;
			#size-cells = <2>;
			reg = <0x0 0x64034000 0x0 0x1000>,
					<0x0 0x30001000 0x0 0x1000>;
			reg-names = "aon", "top";
			#gpio-cells = <2>;

		};

		clkc:c1200bclkc@30002000 {
			status = "disable";
			compatible = "bst,c1200-clkc";
			#clock-cells = <0x1>;
			osc-clk-frequency = <25000000>;
			reg = <	0x0 0x30002000 0x0 0x1000>;	/* TOP_CRM_REG */
		};

		gtc:bstgtc@3000a000 {
			status = "disable";
			compatible = "bst,bst-gtc";
			reg = <0x0 0x3000A000 0x0 0x1000>;
			interrupt-parent = <&gic600>;
			interrupts = <GIC_SPI 126 IRQ_TYPE_LEVEL_HIGH>;
			interrupt-names = "gtc_irq";
			mux_idx = <8>;
		};

		// cpu subsystem csr 3000:3000
		// soc probe 3000:4000
		// timestamp_csr 3000:8000
		// ipc 3010:0000
		// noc 3020:0000 ~~ 3028:0000
		// coresight_ATB 3030:0000
		// soc_dma_hs 3100:0000 ~~ 3125:0000
		// CFG_SOC_CPU 3200:0000 ~~ 3230:0000

		xgmac_axi_setup: stmmac-axi-config {
			snps,wr_osr_lmt = <0x1f>;
			snps,rd_osr_lmt = <0x1f>;
			snps,axi_fb;
			snps,blen = <4 8 16 32 64 128 256>;
		};

		xgmac_mtl_rx_setup: mtl_rx-queues-config {
			snps,rx-queues-to-use = <4>;
			snps,rx-sched-sp;
			queue0 {
				snps,dcb-algorithm;
				snps,map-to-dma-channel = <0x0>;
				// snps,priority = <0x0>;
			};
			queue1 {
				snps,dcb-algorithm;
				snps,route-up;
				snps,map-to-dma-channel = <0x1>;
				// snps,priority = <0x1>;
			};
			queue2 {
				snps,dcb-algorithm;
				snps,route-ptp;
				snps,map-to-dma-channel = <0x2>;
				// snps,priority = <0x2>;
			};
			queue3 {
				snps,dcb-algorithm;
				snps,route-multi-broad;
				snps,map-to-dma-channel = <0x3>;
				// snps,priority = <0x3>;
			};

		};

		xgmac_mtl_tx_setup: mtl_tx-queues-config {
			snps,tx-queues-to-use = <4>;
			snps,tx-sched-wrr;
			queue0 {
				snps,weight = <0x10>;
				snps,dcb-algorithm;
				snps,priority = <0x0>;
			};
			queue1 {
				snps,weight = <0x10>;
				snps,dcb-algorithm;
				snps,priority = <0x1>;
			};
			queue2 {
				snps,weight = <0x10>;
				snps,dcb-algorithm;
				snps,priority = <0x2>;
			};
			queue3 {
				snps,weight = <0x10>;
				snps,dcb-algorithm;
				snps,priority = <0x3>;
			};

		};
		xgmac0: ethernet@32400000 {
			status = "disable";
			eth-name = "xgmac0";
			compatible = "bst,dwxgmac";
			reg = <0x0 0x32400000 0 0x10000>;
			interrupt-parent = <&gic600>;
			interrupts = <GIC_SPI 150 (GIC_CPU_MASK_SIMPLE(4) | IRQ_TYPE_LEVEL_HIGH)
					GIC_SPI 151  (GIC_CPU_MASK_SIMPLE(4) | IRQ_TYPE_LEVEL_HIGH)
					GIC_SPI 152  (GIC_CPU_MASK_SIMPLE(4) | IRQ_TYPE_LEVEL_HIGH)
					GIC_SPI 153  (GIC_CPU_MASK_SIMPLE(4) | IRQ_TYPE_LEVEL_HIGH)
					GIC_SPI 154  (GIC_CPU_MASK_SIMPLE(4) | IRQ_TYPE_LEVEL_HIGH)
					GIC_SPI 155  (GIC_CPU_MASK_SIMPLE(4) | IRQ_TYPE_LEVEL_HIGH)
					GIC_SPI 156  (GIC_CPU_MASK_SIMPLE(4) | IRQ_TYPE_LEVEL_HIGH)
					GIC_SPI 157  (GIC_CPU_MASK_SIMPLE(4) | IRQ_TYPE_LEVEL_HIGH)
					GIC_SPI 162  (GIC_CPU_MASK_SIMPLE(4) | IRQ_TYPE_LEVEL_HIGH)
					GIC_SPI 163  (GIC_CPU_MASK_SIMPLE(4) | IRQ_TYPE_LEVEL_HIGH)
					GIC_SPI 164  (GIC_CPU_MASK_SIMPLE(4) | IRQ_TYPE_LEVEL_HIGH)
					GIC_SPI 165  (GIC_CPU_MASK_SIMPLE(4) | IRQ_TYPE_LEVEL_HIGH)
					GIC_SPI 170  (GIC_CPU_MASK_SIMPLE(4) | IRQ_TYPE_LEVEL_HIGH)
					GIC_SPI 171  (GIC_CPU_MASK_SIMPLE(4) | IRQ_TYPE_LEVEL_HIGH)>;
			interrupt-names = "eth_lpi","sbd_irq", "sfty_ce_irq", "sfty_ue_irq","tx_chan0_irq","tx_chan1_irq","tx_chan2_irq","tx_chan3_irq",
					"rx_chan0_irq","rx_chan1_irq","rx_chan2_irq","rx_chan3_irq","wdata_ucerr_irq","paddr_parity_irq";
			ethernet-id = <0>;
			max-speed = <10000>;
			snps,multicast-filter-bins = <256>;
			snps,perfect-filter-entries = <128>;
			rx-fifo-depth = <16384>;
			tx-fifo-depth = <16384>;
			bst,fix-safety = <0>;
			bst,dma_int_mode = <1>;
			snps,fixed-burst;
			snps,force_sf_dma_mode;
			snps,axi-config = <&xgmac_axi_setup>;
			snps,mtl-rx-config = <&xgmac_mtl_rx_setup>;
			snps,mtl-tx-config = <&xgmac_mtl_tx_setup>;
			label = "xgmac0";
		};

		cooling_dev {
			pwm: pwm {
				cpumask = <0xf>;
				capacitance = <1500>;
				#cooling-cells = <2>;
			};
		};

		thermal-zones {
			cpu_thermal: cpu-thermal {
				polling-delay-passive = <500>;
				polling-delay = <0>;
				thermal-sensors = <&thermal>;

				trips {
					trip0: switch_trip {
						temperature	= <90000>;
						hysteresis	= <2000>;
						type		= "passive";
					};
					crit: critical_trip {
						temperature	= <125000>;
						hysteresis	= <0>;
						type		= "critical";
					};
				};

				cooling-maps {
					map0 {
						trip = <&trip0>;
						cooling-device = <&pwm 0 3>;
					};
				};
			};
		};


		gic600: interrupt-controller@0 {
			compatible = "arm,gic-v3";
			#interrupt-cells = <3>;
			#address-cells = <2>;
			#size-cells = <2>;
			interrupt-controller;
			ranges;
			reg = <0x0 0x32800000 0 0x10000>,	// GICD
				<0x0 0x32880000 0 0x100000>;	// GICR
			interrupt-parent = <&gic600>;
			interrupts = <GIC_PPI 0x9 (GIC_CPU_MASK_SIMPLE(8) | IRQ_TYPE_LEVEL_HIGH)>;

			its0_x4: gic-its@32840000 {
				status = "disable";
				compatible = "arm,gic-v3-its";
				msi-controller;
				#msi-cells = <1>;
				reg = <0x0 0x32840000 0x0 0x20000>;
			};

			its1_x2: gic-its@32860000 {
				status = "disable";
				compatible = "arm,gic-v3-its";
				msi-controller;
				#msi-cells = <1>;
				reg = <0x0 0x32860000 0x0 0x20000>;
			};
		};

		cv_bus: cv_bus {
			#address-cells = <2>;
			#size-cells = <2>;
			compatible = "simple-bus";
			ranges;

			bst_cvsmm: bst-cvsmm {
				#address-cells = <2>;
				#size-cells = <2>;
				status = "disabled";
				compatible = "bst,bst-cvsmm";
			};
		};

		hwcv: bst-hwcv@0x51000000 {
			status = "disabled";
			#address-cells = <2>;
			#size-cells = <2>;
			compatible = "bst,c1200-hwcv";
			reg = <0x0 0x51000000 0x0 0x100>, //CV base
			      <0x0 0x51020000 0x0 0x78>,  //Scaler base
			      <0x0 0x51021000 0x0 0x548>, //Gwarp0 base
			      <0x0 0x51022000 0x0 0x548>; //Gwarp1 base
			interrupt-parent = <&gic600>;
			interrupts = <GIC_SPI 360 (IRQ_TYPE_LEVEL_HIGH)>;
			interrupt-names = "bst-hwcv-irq";
		};

		ipc: bst-ipc {
			status = "disable";
			#address-cells = <0x2>;
			#size-cells = <0x2>;
			compatible = "bst,bst-ipc";
			reg =   <0x0 0x30102000 0x0 0x2000>,
					<0x0 0x30100000 0x0 0x2000>;
			assigned-mem-size = <0x1000>;
		};

		mbox: bst-mbox {
			status = "disable";
			#address-cells = <0x2>;
			#size-cells = <0x2>;
			compatible = "bst,bst-mbox";
			reg =   <0x0 0x30102000 0x0 0x2000>,
					<0x0 0x30100000 0x0 0x2000>;
			assigned-mem-size = <0x1000>;
			ipc-cpus = <2 3>;
			interrupt-parent = <&gic600>;
			interrupts = <
						GIC_SPI 109 (IRQ_TYPE_LEVEL_HIGH)
						GIC_SPI 110 (IRQ_TYPE_LEVEL_HIGH)
						GIC_SPI 111 (IRQ_TYPE_LEVEL_HIGH)
						GIC_SPI 112 (IRQ_TYPE_LEVEL_HIGH)
						GIC_SPI 176 (IRQ_TYPE_LEVEL_HIGH)
						GIC_SPI 177 (IRQ_TYPE_LEVEL_HIGH)>;
		};

		bstnpu: bst-npu@50020000 {
			compatible = "bst,c1200-bstnpu";
			reg = <0x0 0x50020000 0x0 0x100>,
						<0x8 0x10000000 0x0 0x2000000>;
			/* for summu to bypass physical address. */
			bypass_res = <0x0 0x30000000 0x0 0x01000000>,
									<0x0 0x50000000 0x0 0x10000000>,
									<0x8 0x20000000 0x0 0x01000000>;
			status = "disabled";

			npu0@810000000 {
				/* <sreg fw_reg> */
				reg-idx = <0x0 0x1>;
				firmware = "bstn_dsp_rtos.rbf";
				firmware-msgbx = "bstn_dsp_rtos.msgbox.rbf";
				msgbox-pid = <0x17>;
				msgbox-cid = <0x40>;
				msgbox-sid = <0xa>;
				ipc-pid = <0x00>;
				ipc-cid = <0x14>;
			};
		};

		bstdsp: bst-dsp@51000000 {
			compatible = "bst,c1200-bstdsp";
			reg = <0x0 0x51000000 0x0 0x100>,
					<0x8 0x16000000 0x0 0x2000000>,
					<0x8 0x18000000 0x0 0x2000000>,
					<0x8 0x12000000 0x0 0x2000000>,
					<0x8 0x14000000 0x0 0x2000000>;
			/* for summu to bypass physical address. */
			bypass_res = <0x0 0x30000000 0x0 0x01000000>,
									<0x0 0x47000000 0x0 0x01000000>,
									<0x0 0x50000000 0x0 0x10000000>,
									<0x8 0x3e000000 0x0 0x02000000>,
									<0x8 0x00300000 0x0 0x00400000>;
			ipc-reg-addr = <0x8 0x00300000 0x0 0x00400000>;
			status = "disabled";

			dsp0@816000000 {
				reg-idx = <0x0 0x1>;
				firmware = "bst_dsp_rpc_fw0.rbf";
				firmware-msgbx = "bst_dsp_rpc_fw0.rbf";
				firmware-rtinit-offset = <0x007ff000>;
				msgbox-pid = <0x16>;
				msgbox-cid = <0x30>;
				msgbox-sid = <0xb>;
				ipc-pid = <0x03>;
				ipc-cid = <0x10>;
			};

			dsp1@818000000 {
				reg-idx = <0x0 0x2>;
				firmware = "bst_dsp_rpc_fw1.rbf";
				firmware-msgbx = "bst_dsp_rpc_fw1.rbf";
				firmware-rtinit-offset = <0x007ff000>;
				msgbox-pid = <0x16>;
				msgbox-cid = <0x31>;
				msgbox-sid = <0xc>;
				ipc-pid = <0x03>;
				ipc-cid = <0x11>;
			};

			dsp2@812000000 {
				reg-idx = <0x0 0x3>;
				firmware = "bst_dsp_rpc_fw2.rbf";
				firmware-msgbx = "bst_dsp_rpc_fw2.rbf";
				firmware-rtinit-offset = <0x007ff000>;
				msgbox-pid = <0x16>;
				msgbox-cid = <0x32>;
				msgbox-sid = <0xd>;
				ipc-pid = <0x03>;
				ipc-cid = <0x12>;
			};

			dsp3@814000000 {
				reg-idx = <0x0 0x4>;
				firmware = "bst_dsp_rpc_fw3.rbf";
				firmware-msgbx = "bst_dsp_rpc_fw3.rbf";
				firmware-rtinit-offset = <0x007ff000>;
				msgbox-pid = <0x16>;
				msgbox-cid = <0x33>;
				msgbox-sid = <0xe>;
				ipc-pid = <0x03>;
				ipc-cid = <0x13>;
			};
		};

                bstn_bus: bstn_bus {
                        #address-cells = <2>;
                        #size-cells = <2>;
                        compatible = "simple-bus";
                        ranges;
                        bstn: bstn@50020000 {
                                #address-cells = <2>;
                                #size-cells = <2>;
                                status = "disable";
                                compatible = "bst,bstn";
                                id = <0x0>;
                                reg = <0x0 0x50020000 0x0 0x100
                                       0x8 0x10000000 0x0 0x2000000>;
                                assigned-mem-size = <0x1000>;
                                rmem-base = <0xc 0x00000000>;
                                rmem-size = <0x0 0x40000000>;
                                bus-offset = <0x0 0x0>;
                                firmware = "bstn_dsp_rtos.rbf";
                                firmware1 = "bstn_dsp_rtos.msgbox.rbf";
                                msgbox-endid = <0x17>; /* CPU_7 */
                                ipc-src-core = <0x2>;
                        };
                };

		lwnn: bst_lwnn@51000000 {
			status = "disable";
			compatible = "bst,bst_lwnn,cma";
			reg = <0x0 0x51000000 0x0 0x100
					0x8 0x12000000 0x0 0x2000000
					0x8 0x14000000 0x0 0x2000000
					0x8 0x16000000 0x0 0x2000000
					0x8 0x18000000 0x0 0x2000000>;
			bus-offset = <0x0 0x0>;
			dsp-num = <0x4>;
			ipc-register-addr = <0x8ff00000>;
			msgbox-endid = <0x16>; /* CPU_6 */

			dsp@812000000 {
				index = <0x2>;
				firmware = "bst_lwnn_dsp2_rt.rbf";
				firmware1 = "bst_lwnn_dsp2_rt.msgbox.rbf";
				assigned-mem-size = <0x2000>;
				/* old:0x9000 0000, offset: 0x027ff000 */
				/* new:0x6140 0000 + offset: 0x027ff000,  */
				rt-init-addr = <0x63bff000>;
				ipc-src-core = <0x0>;
			};
			dsp@814000000 {
				index = <0x3>;
				firmware = "bst_lwnn_dsp3_rt.rbf";
				firmware1 = "bst_lwnn_dsp3_rt.msgbox.rbf";
				assigned-mem-size = <0x2000>;
				rt-init-addr = <0x65bff000>;
				ipc-src-core = <0x3>;
			};
			dsp@816000000 {
				index = <0x0>;
				firmware = "bst_lwnn_dsp0_rt.rbf";
				firmware1 = "bst_lwnn_dsp0_rt.msgbox.rbf";
				assigned-mem-size = <0x2000>;
				rt-init-addr = <0x67bff000>;
				ipc-src-core = <0x0>;
			};
			dsp@818000000 {
				index = <0x1>;
				firmware = "bst_lwnn_dsp1_rt.rbf";
				firmware1 = "bst_lwnn_dsp1_rt.msgbox.rbf";
				assigned-mem-size = <0x2000>;
				rt-init-addr = <0x69bff000>;
				ipc-src-core = <0x1>;
			};
		};

		// CFG_DB_CPU 33000000 ~~ 3330:0000
		// gic 33200000
		// msgbox 0x33300000
		// DB_SUBSYSTEM 3400:0000 ~~ 3480:0000  include dma、gpu


		// coreip 5000:0000 ~~ 5FFF:FFFF  include net、cv、isp、mipi、coreip_mem
		// cmn 0:6000:0000	0:63FF:FFFF
		// DDR_CTRL	0:7000:0000

		arm_pmu: arm_pmu {   // menuconfig PERF_EVENTS
		status = "disable";
		compatible = "arm,armv8-pmuv3";
		interrupt-parent = <&gic600>;
		interrupts = <GIC_PPI 7 IRQ_TYPE_LEVEL_HIGH>;
		};

		gmac_axi_setup: axi-config {
			snps,wr_osr_lmt = <0xf>;
			snps,rd_osr_lmt = <0xf>;
			snps,axi_fb;
			snps,blen = <4 8 16 0 0 0 0>;
		};
		gmac_mtl_rx_setup: rx-queues-config {
			snps,rx-queues-to-use = <4>;
			snps,rx-sched-sp;
			queue0 {
				snps,dcb-algorithm;
				snps,map-to-dma-channel = <0x0>;
				snps,priority = <0x0>;
			};
			queue1 {
				snps,dcb-algorithm;
				snps,map-to-dma-channel = <0x1>;
				snps,priority = <0x1>;
			};
			queue2 {
				snps,dcb-algorithm;
				snps,map-to-dma-channel = <0x2>;
				snps,priority = <0x2>;
			};
			queue3 {
				snps,dcb-algorithm;
				snps,map-to-dma-channel = <0x3>;
				snps,priority = <0x3>;
			};
		};

		gmac_mtl_tx_setup: tx-queues-config {
			snps,tx-queues-to-use = <4>;
			snps,tx-sched-wrr;
			queue0 {
				snps,weight = <0x10>;
				snps,dcb-algorithm;
				snps,priority = <0x0>;
			};

			queue1 {
				snps,weight = <0x10>;
				snps,dcb-algorithm;
				snps,priority = <0x1>;
			};
			queue2 {
				snps,weight = <0x10>;
				snps,dcb-algorithm;
				snps,priority = <0x2>;
			};
			queue3 {
				snps,weight = <0x10>;
				snps,dcb-algorithm;
				snps,priority = <0x3>;
			};
		};
		gmac0: ethernet@217b8000 {
			status = "disable";
			compatible = "bst,sw-gmac";
			reg = <0x0 0x217b8000 0 0x8000>;
			interrupt-parent = <&gic600>;
			//sw_to_soc
			interrupts = <GIC_SPI 488  (GIC_CPU_MASK_SIMPLE(8) | IRQ_TYPE_LEVEL_HIGH)
							GIC_SPI 489  (GIC_CPU_MASK_SIMPLE(8) | IRQ_TYPE_LEVEL_HIGH)
							GIC_SPI 490  (GIC_CPU_MASK_SIMPLE(8) | IRQ_TYPE_LEVEL_HIGH)
							GIC_SPI 491  (GIC_CPU_MASK_SIMPLE(8) | IRQ_TYPE_LEVEL_HIGH)
							GIC_SPI 492  (GIC_CPU_MASK_SIMPLE(8) | IRQ_TYPE_LEVEL_HIGH)
							GIC_SPI 493  (GIC_CPU_MASK_SIMPLE(8) | IRQ_TYPE_LEVEL_HIGH)
							GIC_SPI 494  (GIC_CPU_MASK_SIMPLE(8) | IRQ_TYPE_LEVEL_HIGH)
							GIC_SPI 495  (GIC_CPU_MASK_SIMPLE(8) | IRQ_TYPE_LEVEL_HIGH)
							GIC_SPI 496  (GIC_CPU_MASK_SIMPLE(8) | IRQ_TYPE_LEVEL_HIGH)
							GIC_SPI 497  (GIC_CPU_MASK_SIMPLE(8) | IRQ_TYPE_LEVEL_HIGH)
							GIC_SPI 498  (GIC_CPU_MASK_SIMPLE(8) | IRQ_TYPE_LEVEL_HIGH)>;
			interrupt-names = "sbd_irq", "rx_chan0_irq","rx_chan1_irq","rx_chan2_irq","rx_chan3_irq",
								"tx_chan0_irq","tx_chan1_irq","tx_chan2_irq","tx_chan3_irq",
								"sfty_ue_irq", "sfty_ce_irq";
			ethernet-id = <0>;
			max-speed = <1000>;
			snps,multicast-filter-bins = <256>;
			snps,perfect-filter-entries = <128>;
			rx-fifo-depth = <8192>;
			tx-fifo-depth = <8192>;
			bst,fix-safety = <0>;
			bst,dma_int_mode = <1>;
			snps,fixed-burst;
			snps,force_sf_dma_mode;
			//snps,force_thresh_dma_mode;
			snps,ps-speed = <1000>;
			snps,axi-config = <&gmac_axi_setup>;
			snps,mtl-rx-config = <&gmac_mtl_rx_setup>;
			snps,mtl-tx-config = <&gmac_mtl_tx_setup>;
			label = "gmac0";
		};

		virtouch: virt-touchscreen {
			status = "disable";
			compatible = "bst,virt-ts";
		};

		sqbuffer: sq-buffer {
			status = "disable";
			compatible = "bst,sqbuffer";
		};

		backlight_lvds0: bst_backlight@0 {
			status = "disable";
			compatible = "bst,virt-backlight";
			screen-id = <0x0>;
			//default-brightness-level = <50>;    /* Default brightness (optional), uses max_brightness/2 if not set */
		};
		backlight_lvds1: bst_backlight@1 {
			status = "disable";
			compatible = "bst,virt-backlight";
			screen-id = <0x1>;
		};
		backlight_dsi0: bst_backlight@2 {
			status = "disable";
			compatible = "bst,virt-backlight";
			screen-id = <0x2>;
		};
		backlight_dsi1: bst_backlight@3 {
			status = "disable";
			compatible = "bst,virt-backlight";
			screen-id = <0x3>;
		};
		backlight_edp: bst_backlight@4 {
			status = "disable";
			compatible = "bst,virt-backlight";
			screen-id = <0x4>;
		};
	};

	isp_bus: isp-bus@0 {
		compatible = "simple-bus";
		#address-cells = <0x2>;
		#size-cells = <0x2>;
		ranges;

		/* This default dma-ranges is used for no-SMMU scene */
		dma-ranges = <0x0 0xC0000000 0xC 0x00000000 0x0 0x3E000000>,	// High 1G-32M RAM
			     <0x0 0x80000000 0x8 0x00000000 0x0 0x3E000000>,	// Low 1G-32M RAM
			     <0x0 0x3E000000 0x0 0x3E000000 0x0 0x02000000>,	// Reserved to restrict IOVA area
			     <0x0 0x40000000 0x0 0x20000000 0x0 0x07000000>,	// Outer registers area
			     <0x0 0x47000000 0x0 0x30000000 0x0 0x01000000>,	// Outer registers area
			     <0x0 0x50000000 0x0 0x50000000 0x0 0x10000000>;	// ISPCV inner registers

		i2cq0: i2cq@5203e000 {
			compatible = "bst,c1200-i2cq";
			reg = <0x0 0x5203e000 0 0x800>, // I2CQ base
			      <0x0 0x52030000 0 0x100>; // Top Ctrl
			clock-frequency = <937500>;
			interrupt-parent = <&gic600>;
			interrupts = <GIC_SPI 380 IRQ_TYPE_LEVEL_HIGH>;
			resets = <&scmi_reset RST_ISP_SW>;
			reset-names = "i2cq-reset";
			i2c-nr = <9>;
			#address-cells = <1>;
			#size-cells = <0>;
			id = <0>;
			status = "disabled";
		};

		i2cq1: i2cq@5203e800 {
			compatible = "bst,c1200-i2cq";
			reg = <0x0 0x5203e800 0 0x800>, // I2CQ base
			      <0x0 0x52030000 0 0x100>; // Top Ctrl
			clock-frequency = <937500>;
			interrupt-parent = <&gic600>;
			interrupts = <GIC_SPI 381 IRQ_TYPE_LEVEL_HIGH>;
			resets = <&scmi_reset RST_ISP_SW>;
			reset-names = "i2cq-reset";
			i2c-nr = <10>;
			#address-cells = <1>;
			#size-cells = <0>;
			id = <1>;
			status = "disabled";
		};

		i2cq2: i2cq@5203f000 {
			compatible = "bst,c1200-i2cq";
			reg = <0x0 0x5203f000 0 0x800>, // I2CQ base
			      <0x0 0x52030000 0 0x100>; // Top Ctrl
			clock-frequency = <937500>;
			interrupt-parent = <&gic600>;
			interrupts = <GIC_SPI 382 IRQ_TYPE_LEVEL_HIGH>;
			resets = <&scmi_reset RST_ISP_SW>;
			reset-names = "i2cq-reset";
			i2c-nr = <8>;
			#address-cells = <1>;
			#size-cells = <0>;
			id = <2>;
			status = "disabled";
		};

		csi0: csi@53000000 {
			compatible = "bst,c1200-csi2-rx";
			reg = <0x0 0x53000000 0x0 0x00015500>,
			      <0x0 0x53015500 0x0 0x00000100>;
			interrupt-parent = <&gic600>;
			interrupts = <GIC_SPI 361 (IRQ_TYPE_LEVEL_HIGH)>,
				     <GIC_SPI 362 (IRQ_TYPE_LEVEL_HIGH)>;
			resets = <&scmi_reset RST_MIPI0_CSIRX_SW>;
			reset-names = "csi-reset";
			clock-lanes = <0>;
			data-lanes = <1 2 3 4>;
			lane-speed = <2500>;
			id = <0>;
			status = "disabled";

			rx-ports {
				port@0 {
					csi0_in: endpoint@0{
					};
				};
			};
			ports {
				#address-cells = <1>;
				#size-cells = <0>;
				port@0 {
					reg = <0>;
					csi0_out0: endpoint@0 {
					};
				};
				port@1 {
					reg = <1>;
					csi0_out1: endpoint@1 {
					};
				};
				port@2 {
					reg = <2>;
					csi0_out2: endpoint@2 {
					};
				};
				port@3 {
					reg = <3>;
					csi0_out3: endpoint@3 {
					};
				};
			};
		};

		csi1: csi@53100000 {
			compatible = "bst,c1200-csi2-rx";
			reg = <0x0 0x53100000 0x0 0x00015500>,
			      <0x0 0x53115500 0x0 0x00000100>;
			interrupt-parent = <&gic600>;
			interrupts = <GIC_SPI 363 (IRQ_TYPE_LEVEL_HIGH)>,
				     <GIC_SPI 364 (IRQ_TYPE_LEVEL_HIGH)>;
			resets = <&scmi_reset RST_MIPI1_CSIRX_SW>;
			reset-names = "csi-reset";
			clock-lanes = <0>;
			data-lanes = <1 2 3 4>;
			lane-speed = <2500>;
			id = <1>;
			status = "disabled";

			rx-ports {
				port@0 {
					csi1_in: endpoint@0{
					};
				};
			};
			ports {
				#address-cells = <1>;
				#size-cells = <0>;
				port@0 {
					reg = <0>;
					csi1_out0: endpoint@0 {
					};
				};
				port@1 {
					reg = <1>;
					csi1_out1: endpoint@1 {
					};
				};
				port@2 {
					reg = <2>;
					csi1_out2: endpoint@2 {
					};
				};
				port@3 {
					reg = <3>;
					csi1_out3: endpoint@3 {
					};
				};
			};
		};

		csi2: csi@53200000 {
			compatible = "bst,c1200-csi2-rx";
			reg = <0x0 0x53200000 0x0 0x00015500>,
			      <0x0 0x53215500 0x0 0x00000100>;
			interrupt-parent = <&gic600>;
			interrupts = <GIC_SPI 365 (IRQ_TYPE_LEVEL_HIGH)>,
				     <GIC_SPI 366 (IRQ_TYPE_LEVEL_HIGH)>;
			resets = <&scmi_reset RST_MIPI2_CSIRX_SW>;
			reset-names = "csi-reset";
			clock-lanes = <0>;
			data-lanes = <1 2 3 4>;
			lane-speed = <2500>;
			id = <2>;
			status = "disabled";

			rx-ports {
				port@0 {
					csi2_in: endpoint@0{
					};
				};
			};
			ports {
				#address-cells = <1>;
				#size-cells = <0>;
				port@0 {
					reg = <0>;
					csi2_out0: endpoint@0 {
					};
				};
				port@1 {
					reg = <1>;
					csi2_out1: endpoint@1 {
					};
				};
				port@2 {
					reg = <2>;
					csi2_out2: endpoint@2 {
					};
				};
				port@3 {
					reg = <3>;
					csi2_out3: endpoint@3 {
					};
				};
			};
		};

		isp: isp@52030000 {
			compatible = "bst,c1200-isp";
			reg = <0x0 0x52030000 0 0x1000>,	// Top Ctrl
			      <0x0 0x52040000 0 0x40000>,	// PRAM
			      <0x0 0x47000000 0 0x01000000>,	// GTC, IPC, etc
			      <0x0 0x40000000 0 0x07000000>;	// I2C controller, etc
			resets = <&scmi_reset RST_ISP_SW>;
			reset-names = "isp-reset";
			status = "disabled";

			ports {
				#address-cells = <1>;
				#size-cells = <0>;

				port@0 {
					reg = <0>;
					isp_chn0: endpoint@0 {
					};
				};
				port@1 {
					reg = <1>;
					isp_chn1: endpoint@1 {
					};
				};
				port@2 {
					reg = <2>;
					isp_chn2: endpoint@2 {
					};
				};
				port@3 {
					reg = <3>;
					isp_chn3: endpoint@3 {
					};
				};
				port@4 {
					reg = <4>;
						isp_chn4: endpoint@4 {
						};
					};
				port@5 {
					reg = <5>;
						isp_chn5: endpoint@5 {
						};
					};
				port@6 {
					reg = <6>;
						isp_chn6: endpoint@6 {
						};
					};
				port@7 {
					reg = <7>;
						isp_chn7: endpoint@7 {
					};
				};
				port@8 {
					reg = <8>;
					isp_chn8: endpoint@8 {
					};
				};
				port@9 {
					reg = <9>;
					isp_chn9: endpoint@9 {
					};
				};
				port@a {
					reg = <10>;
					isp_chn10: endpoint@10 {
					};
				};
				port@b {
					reg = <11>;
					isp_chn11: endpoint@11 {
					};
				};
				port@c {
					reg = <12>;
					isp_chn12: endpoint@12 {
					};
				};
				port@d {
					reg = <13>;
					isp_chn13: endpoint@13 {
					};
				};
				port@e {
					reg = <14>;
					isp_chn14: endpoint@14 {
					};
				};
				port@f {
					reg = <15>;
					isp_chn15: endpoint@15 {
					};
				};
			};
		};
	};
};

&spi0 {
	status = "disable";
	slave@0 {
		compatible = "micron,spi-authenta";
		reg = <0>;
		spi-mode = <0>; /* spi_mode: 0-3 */
		spi-max-frequency = <400000>;
	};
};

&spi1 {
	status = "disable";
	slave@0 {
		compatible = "micron,spi-authenta";
		spi-mode = <0>; /* spi_mode: 0-3 */
		spi-max-frequency = <400000>;
	};
};

&spi2 {
	status = "disable";
	slave@0 {
		compatible = "micron,spi-authenta";
		reg = <0>;
		spi-mode = <0>; /* spi_mode: 0-3 */
		spi-max-frequency = <400000>;
	};
};

&spi3 {
	status = "disable";
	slave@0 {
		compatible = "micron,spi-authenta";
		spi-mode = <0>; /* spi_mode: 0-3 */
		spi-max-frequency = <400000>;
	};
};

